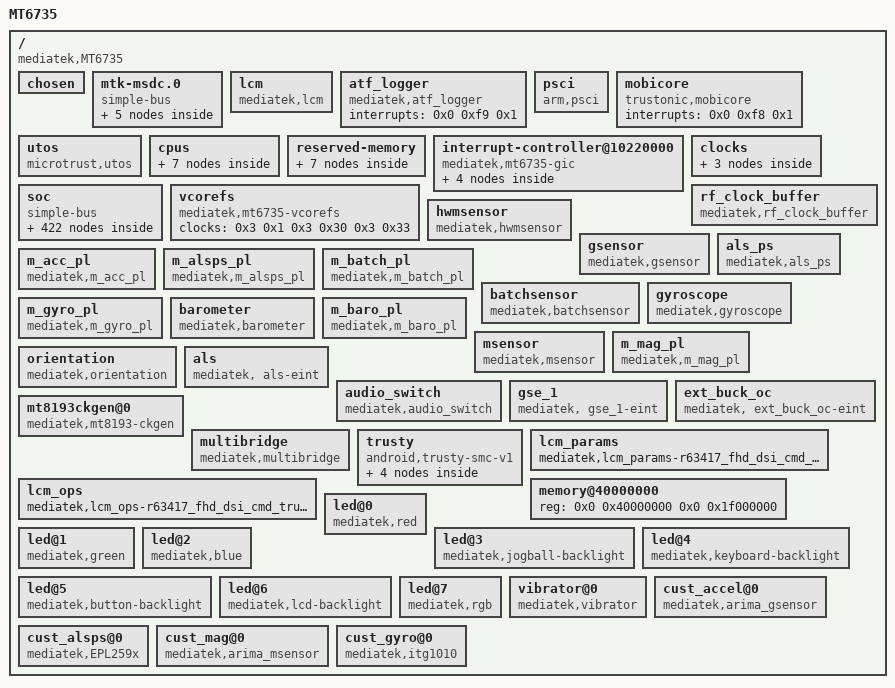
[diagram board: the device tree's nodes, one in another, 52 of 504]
/dts-v1/;

/ {
	model = "MT6735";
	compatible = "mediatek,MT6735";
	interrupt-parent = <0x1>;
	#address-cells = <0x2>;
	#size-cells = <0x2>;

	chosen {
		bootargs = "console=tty0 console=ttyMT0,921600n1 root=/dev/ram initrd=0x44000000,0x300000 loglevel=8 androidboot.hardware=mt6735";
	};

	mtk-msdc.0 {
		compatible = "simple-bus";
		#address-cells = <0x1>;
		#size-cells = <0x1>;
		ranges = <0x0 0x0 0x0 0xffffffff>;

		msdc0@11230000 {
			compatible = "mediatek,mt6735-mmc";
			reg = <0x11230000 0x10000 0x10000e84 0x2>;
			interrupts = <0x0 0x4f 0x8>;
			status = "okay";
			clocks = <0x2 0xe 0x3 0xd 0x3 0x29 0x3 0x2b 0x3 0x2c>;
			clock-names = "MSDC0-CLOCK", "MSDC0_PLL_SEL", "MSDC0_PLL_800M", "MSDC0_PLL_400M", "MSDC0_PLL_200M";
			clk_src = [02];
			bus-width = <0x8>;
			max-frequency = <0xbebc200>;
			cap-mmc-highspeed;
			msdc-sys-suspend;
			mmc-ddr-1_8v;
			mmc-hs200-1_8v;
			mmc-hs400-1_8v;
			non-removable;
			pinctl = <0x4>;
			register_setting = <0x5>;
			host_function = [00];
			bootable;
		};

		msdc1@11240000 {
			compatible = "mediatek,mt6735-mmc";
			reg = <0x11240000 0x10000 0x10000e84 0x2>;
			interrupts = <0x0 0x50 0x8>;
			status = "okay";
			clocks = <0x2 0xf>;
			clock-names = "MSDC1-CLOCK";
			clk_src = [02];
			bus-width = <0x4>;
			max-frequency = <0xbebc200>;
			msdc-sys-suspend;
			cap-sd-highspeed;
			sd-uhs-sdr12;
			sd-uhs-sdr25;
			sd-uhs-sdr50;
			sd-uhs-sdr104;
			sd-uhs-ddr50;
			pinctl = <0x6>;
			pinctl_sdr104 = <0x7>;
			pinctl_sdr50 = <0x8>;
			pinctl_ddr50 = <0x9>;
			register_setting = <0xa>;
			host_function = [01];
			cd_level = [00];
			cd-gpios = <0xb 0x5 0x0>;
		};

		msdc2@11250000 {
			compatible = "mediatek,mt6735-mmc";
			reg = <0x11250000 0x10000 0x10000e84 0x2>;
			interrupts = <0x0 0x51 0x8>;
			status = "disabled";
			clocks = <0x2 0x10>;
			clock-names = "MSDC2-CLOCK";
		};

		msdc3@11260000 {
			compatible = "mediatek,mt6735-mmc";
			reg = <0x11260000 0x10000 0x10000e84 0x2>;
			interrupts = <0x0 0x52 0x8>;
			status = "okay";
			clocks = <0x2 0x11>;
			clock-names = "MSDC3-CLOCK";
			clk_src = [02];
			bus-width = <0x4>;
			max-frequency = <0x2faf080>;
			cap-sd-highspeed;
			sd-uhs-sdr12;
			sd-uhs-sdr25;
			sd-uhs-sdr50;
			host_function = [02];
			non-removable;
		};

		default {
			compatible = "mediatek, msdc1_ins-eint";
			interrupt-parent = <0xc>;
			interrupts = <0x5 0x8>;
			debounce = <0x5 0x3e8>;
			status = "okay";
		};
	};

	lcm {
		compatible = "mediatek,lcm";
	};

	atf_logger {
		compatible = "mediatek,atf_logger";
		interrupts = <0x0 0xf9 0x1>;
	};

	psci {
		compatible = "arm,psci";
		method = "smc";
		cpu_suspend = <0x84000001>;
		cpu_off = <0x84000002>;
		cpu_on = <0x84000003>;
		affinity_info = <0x84000004>;
	};

	mobicore {
		compatible = "trustonic,mobicore";
		interrupts = <0x0 0xf8 0x1>;
	};

	utos {
		compatible = "microtrust,utos";
		interrupts = <0x0 0xf4 0x1 0x0 0xf5 0x1 0x0 0xf6 0x1 0x0 0xfa 0x1 0x0 0xfb 0x1 0x0 0xfc 0x1 0x0 0xfd 0x1 0x0 0xff 0x1>;
	};

	cpus {
		#address-cells = <0x1>;
		#size-cells = <0x0>;

		cpu@000 {
			device_type = "cpu";
			compatible = "arm,cortex-a53";
			reg = <0x0>;
			enable-method = "mt-boot";
			cpu-idle-states = <0xd 0xd 0xe 0xe>;
			cpu-release-addr = <0x0 0x40000200>;
			clock-frequency = "M|m";
			linux,phandle = <0xf>;
			phandle = <0xf>;
		};

		cpu@001 {
			device_type = "cpu";
			compatible = "arm,cortex-a53";
			reg = <0x1>;
			enable-method = "mt-boot";
			cpu-idle-states = <0xd 0xd 0xe 0xe>;
			cpu-release-addr = <0x0 0x40000200>;
			clock-frequency = "M|m";
			linux,phandle = <0x10>;
			phandle = <0x10>;
		};

		cpu@002 {
			device_type = "cpu";
			compatible = "arm,cortex-a53";
			reg = <0x2>;
			enable-method = "mt-boot";
			cpu-idle-states = <0xd 0xd 0xe 0xe>;
			cpu-release-addr = <0x0 0x40000200>;
			clock-frequency = "M|m";
			linux,phandle = <0x11>;
			phandle = <0x11>;
		};

		cpu@003 {
			device_type = "cpu";
			compatible = "arm,cortex-a53";
			reg = <0x3>;
			enable-method = "mt-boot";
			cpu-idle-states = <0xd 0xd 0xe 0xe>;
			cpu-release-addr = <0x0 0x40000200>;
			clock-frequency = "M|m";
			linux,phandle = <0x12>;
			phandle = <0x12>;
		};

		idle-states {
			entry-method = "arm,psci";

			cpu-sleep-0-0 {
				compatible = "arm,idle-state";
				arm,psci-suspend-param = <0x10000>;
				entry-latency-us = <0x258>;
				exit-latency-us = <0x258>;
				min-residency-us = <0x4b0>;
				linux,phandle = <0xe>;
				phandle = <0xe>;
			};

			cluster-sleep-0 {
				compatible = "arm,idle-state";
				arm,psci-suspend-param = <0x1010000>;
				entry-latency-us = <0x320>;
				exit-latency-us = <0x3e8>;
				min-residency-us = <0x7d0>;
				linux,phandle = <0xd>;
				phandle = <0xd>;
			};
		};
	};

	reserved-memory {
		#address-cells = <0x2>;
		#size-cells = <0x2>;
		ranges;

		atf-reserved-memory@43000000 {
			compatible = "mediatek,mt6735-atf-reserved-memory", "mediatek,mt6735m-atf-reserved-memory", "mediatek,mt6753-atf-reserved-memory";
			no-map;
			reg = <0x0 0x43000000 0x0 0x30000>;
		};

		ram_console-reserved-memory@43f00000 {
			compatible = "mediatek,ram_console";
			reg = <0x0 0x43f00000 0x0 0x10000>;
		};

		pstore-reserved-memory@43f10000 {
			compatible = "mediatek,pstore";
			reg = <0x0 0x43f10000 0x0 0xe0000>;
		};

		minirdump-reserved-memory@43ff0000 {
			compatible = "mediatek,minirdump";
			reg = <0x0 0x43ff0000 0x0 0x10000>;
		};

		reserve-memory-ccci_md1 {
			compatible = "mediatek,reserve-memory-ccci_md1";
			no-map;
			size = <0x0 0x3810000>;
			alignment = <0x0 0x2000000>;
			alloc-ranges = <0x0 0x40000000 0x0 0xc0000000>;
		};

		consys-reserve-memory {
			compatible = "mediatek,consys-reserve-memory";
			no-map;
			size = <0x0 0x100000>;
			alignment = <0x0 0x200000>;
		};

		reserve-memory-ccci_md3 {
			compatible = "mediatek,reserve-memory-ccci_md3";
			no-map;
			size = <0x0 0xb00000>;
			alignment = <0x0 0x2000000>;
			alloc-ranges = <0x0 0x40000000 0x0 0xc0000000>;
		};
	};

	interrupt-controller@10220000 {
		compatible = "mediatek,mt6735-gic";
		#interrupt-cells = <0x3>;
		#address-cells = <0x0>;
		interrupt-controller;
		reg = <0x0 0x10221000 0x0 0x1000 0x0 0x10222000 0x0 0x1000 0x0 0x10200620 0x0 0x1000>;
		mediatek,wdt_irq = <0xa0>;
		linux,phandle = <0x1>;
		phandle = <0x1>;

		gic-cpuif@0 {
			compatible = "arm,gic-cpuif";
			cpuif-id = <0x0>;
			cpu = <0xf>;
		};

		gic-cpuif@1 {
			compatible = "arm,gic-cpuif";
			cpuif-id = <0x1>;
			cpu = <0x10>;
		};

		gic-cpuif@2 {
			compatible = "arm,gic-cpuif";
			cpuif-id = <0x2>;
			cpu = <0x11>;
		};

		gic-cpuif@3 {
			compatible = "arm,gic-cpuif";
			cpuif-id = <0x3>;
			cpu = <0x12>;
		};
	};

	clocks {

		clk_null {
			compatible = "fixed-clock";
			#clock-cells = <0x0>;
			clock-frequency = <0x0>;
		};

		clk26m {
			compatible = "fixed-clock";
			#clock-cells = <0x0>;
			clock-frequency = <0x18cba80>;
			linux,phandle = <0x3d>;
			phandle = <0x3d>;
		};

		clk32k {
			compatible = "fixed-clock";
			#clock-cells = <0x0>;
			clock-frequency = <0x7d00>;
		};
	};

	soc {
		compatible = "simple-bus";
		#address-cells = <0x1>;
		#size-cells = <0x1>;
		ranges = <0x0 0x0 0x0 0xffffffff>;

		topckgen@10210000 {
			compatible = "mediatek,mt6735-topckgen";
			reg = <0x10210000 0x1000>;
			#clock-cells = <0x1>;
			linux,phandle = <0x3>;
			phandle = <0x3>;
		};

		chipid@08000000 {
			compatible = "mediatek,chipid";
			reg = <0x8000000 0x4 0x8000004 0x4 0x8000008 0x4 0x800000c 0x4>;
		};

		infrasys@10000000 {
			compatible = "mediatek,mt6735-infrasys";
			reg = <0x10000000 0x1000>;
			#clock-cells = <0x1>;
			linux,phandle = <0x19>;
			phandle = <0x19>;
		};

		scpsys@10000000 {
			compatible = "mediatek,mt6735-scpsys";
			reg = <0x10000000 0x1000 0x10006000 0x1000>;
			#clock-cells = <0x1>;
			linux,phandle = <0x13>;
			phandle = <0x13>;
		};

		infracfg_ao@10000000 {
			compatible = "mediatek,infracfg_ao";
			reg = <0x10000000 0x1000>;
		};

		usb2jtag@10000000 {
			compatible = "mediatek,usb2jtag_v1";
			reg = <0x10000000 0x1000 0x11210000 0x1000>;
		};

		pwrap@10001000 {
			compatible = "mediatek,PWRAP";
			reg = <0x10001000 0x1000>;
			interrupts = <0x0 0xa3 0x4>;
		};

		perisys@10002000 {
			compatible = "mediatek,mt6735-perisys";
			reg = <0x10002000 0x1000>;
			#clock-cells = <0x1>;
			linux,phandle = <0x2>;
			phandle = <0x2>;
		};

		hacc@10008000 {
			compatible = "mediatek,hacc";
			reg = <0x10008000 0x1000>;
			interrupts = <0x0 0xae 0x8>;
		};

		pericfg@10002000 {
			compatible = "mediatek,pericfg";
			reg = <0x10002000 0x1000>;
		};

		keypad@10003000 {
			compatible = "mediatek,mt6735-keypad";
			reg = <0x10003000 0x1000>;
			interrupts = <0x0 0xa4 0x2>;
			mediatek,kpd-key-debounce = <0x400>;
			mediatek,kpd-sw-pwrkey = <0x74>;
			mediatek,kpd-hw-pwrkey = <0x8>;
			mediatek,kpd-sw-rstkey = <0x73>;
			mediatek,kpd-hw-rstkey = <0x11>;
			mediatek,kpd-use-extend-type = <0x0>;
			mediatek,kpd-hw-map-num = <0x48>;
			mediatek,kpd-hw-init-map = <0x0 0x72 0x0 0x0 0x0 0x0 0x0 0x0 0x0 0x0 0x0 0x0 0x0 0x0 0x0 0x0 0x0 0x0 0x0 0x0 0x0 0x0 0x0 0x0 0x0 0x0 0x0 0x0 0x0 0x0 0x0 0x0 0x0 0x0 0x0 0x0 0x0 0x0 0x0 0x0 0x0 0x0 0x0 0x0 0x0 0x0 0x0 0x0 0x0 0x0 0x0 0x0 0x0 0x0 0x0 0x0 0x0 0x0 0x0 0x0 0x0 0x0 0x0 0x0 0x0 0x0 0x0 0x0 0x0 0x0 0x0 0x0>;
			mediatek,kpd-pwrkey-eint-gpio = <0x0>;
			mediatek,kpd-pwkey-gpio-din = <0x0>;
			mediatek,kpd-hw-dl-key0 = <0x11>;
			mediatek,kpd-hw-dl-key1 = <0x1>;
			mediatek,kpd-hw-dl-key2 = <0x8>;
			mediatek,kpd-hw-recovery-key = <0x11>;
			mediatek,kpd-hw-factory-key = <0x1>;
			status = "okay";
		};

		apxgpt@10004000 {
			compatible = "mediatek,mt6735-apxgpt";
			reg = <0x10004000 0x1000>;
			interrupts = <0x0 0x98 0x8>;
			clock-frequency = <0xc65d40>;
		};

		eintc@10005000 {
			compatible = "mediatek,mt-eic";
			reg = <0x10005000 0x1000>;
			interrupts = <0x0 0x99 0x4>;
			#interrupt-cells = <0x2>;
			interrupt-controller;
			mediatek,max_eint_num = <0xd5>;
			mediatek,mapping_table_entry = <0x0>;
			mediatek,debtime_setting_entry = <0xa>;
			mediatek,debtime_setting_array = <0x0 0x7d 0x1 0xfa 0x2 0x1f4 0x3 0x3e8 0x4 0x3e80 0x5 0x7d00 0x6 0xfa00 0x7 0x1f400 0x8 0x3e800 0x9 0x7d000>;
			linux,phandle = <0xc>;
			phandle = <0xc>;

			pmic@206 {
				compatible = "mediatek, pmic-eint";
				interrupt-parent = <0xc>;
				interrupts = <0xce 0x4>;
				debounce = <0xce 0x3e8>;
			};

			MD1_SIM1_HOT_PLUG_EINT@0 {
				compatible = "mediatek,MD1_SIM1_HOT_PLUG_EINT-eint";
				interrupts = <0x0 0x4>;
				debounce = <0x0 0x186a0>;
				dedicated = <0x0 0x0>;
				src_pin = <0x0 0x1>;
				sockettype = <0x0 0x0>;
				status = "okay";
			};
		};

		sleep@10006000 {
			compatible = "mediatek,sleep";
			reg = <0x10006000 0x1000>;
			interrupts = <0x0 0xa5 0x8 0x0 0xa6 0x8 0x0 0xa7 0x8 0x0 0xa8 0x8>;
		};

		mdcldma@1000A000 {
			compatible = "mediatek,mdcldma";
			reg = <0x1000a000 0x1000 0x1000b000 0x1000 0x1021a000 0x1000 0x1021b000 0x1000 0x1020a000 0x1000 0x1020b000 0x1000>;
			interrupts = <0x0 0x91 0x4 0x0 0x8c 0x8 0x0 0xdd 0x2>;
			mediatek,md_id = <0x0>;
			mediatek,cldma_capability = <0x6>;
			mediatek,md_smem_size = <0x10000>;
			clocks = <0x13 0x1>;
			clock-names = "scp-sys-md1-main";
			pinctrl-names = "default", "vsram_output_low", "vsram_output_high", "RFIC0_01_mode", "RFIC0_04_mode";
			pinctrl-0 = <0x14>;
			pinctrl-1 = <0x15>;
			pinctrl-2 = <0x16>;
			pinctrl-3 = <0x17>;
			pinctrl-4 = <0x18>;
		};

		mcucfg@10200000 {
			compatible = "mediatek,mcucfg";
			reg = <0x10200000 0x200>;
			interrupts = <0x0 0x47 0x4>;
		};

		cpuxgpt@10200000 {
			compatible = "mediatek,mt6735-cpuxgpt";
			reg = <0x10200000 0x1000>;
			interrupts = <0x0 0x40 0x4 0x0 0x41 0x4 0x0 0x42 0x4 0x0 0x43 0x4 0x0 0x44 0x4 0x0 0x45 0x4 0x0 0x46 0x4 0x0 0x47 0x4>;
		};

		lastpc@10200000 {
			compatible = "mediatek,mt6735-mcucfg";
			reg = <0x10200000 0x200>;
			interrupts = <0x0 0x47 0x4>;
		};

		emi@10203000 {
			compatible = "mediatek,emi";
			reg = <0x10203000 0x1000>;
			interrupts = <0x0 0x88 0x4>;
		};

		sys_cirq@10204000 {
			compatible = "mediatek,mt6735-sys_cirq";
			reg = <0x10204000 0x1000>;
			interrupts = <0x0 0xe7 0x8>;
			mediatek,cirq_num = <0x9f>;
			mediatek,spi_start_offset = <0x48>;
		};

		m4u@10205000 {
			cell-index = <0x0>;
			compatible = "mediatek,m4u";
			reg = <0x10205000 0x1000>;
			interrupts = <0x0 0x92 0x8>;
			clocks = <0x19 0x9 0x1a 0x1 0x1a 0x2 0x1b 0x1 0x1b 0x2 0x1c 0x1 0x1d 0x2 0x1d 0x1>;
			clock-names = "infra_m4u", "smi_common", "m4u_disp0_smi_larb0", "m4u_vdec0_vdec", "m4u_vdec1_larb", "m4u_img_image_larb2_smi", "m4u_venc_venc", "m4u_venc_larb";
		};

		efusec@10206000 {
			compatible = "mediatek,efusec";
			reg = <0x10206000 0x1000>;
		};

		devapc@10207000 {
			compatible = "mediatek,devapc";
			reg = <0x10207000 0x1000>;
			interrupts = <0x0 0x86 0x8>;
			clocks = <0x19 0x5>;
			clock-names = "devapc-main";
		};

		bus_dbg@10208000 {
			compatible = "mediatek,bus_dbg-v1";
			reg = <0x10208000 0x1000>;
			interrupts = <0x0 0x89 0x8>;
		};

		apmixedsys@10209000 {
			compatible = "mediatek,mt6735-apmixedsys";
			reg = <0x10209000 0x1000>;
			#clock-cells = <0x1>;
			linux,phandle = <0x3c>;
			phandle = <0x3c>;
		};

		apmixed@10209000 {
			compatible = "mediatek,apmixed";
			reg = <0x10209000 0x1000>;
		};

		fhctl@10209f00 {
			compatible = "mediatek,fhctl";
			reg = <0x10209f00 0x100>;
		};

		dramc_nao@1020e000 {
			compatible = "mediatek,mt6735-dramc_nao";
			reg = <0x1020e000 0x1000>;
		};

		cksys@10210000 {
			compatible = "mediatek,cksys";
			reg = <0x10210000 0x1000>;
		};

		syscfg_pctl_a@10211000 {
			compatible = "mediatek,mt6735-pctl-a-syscfg", "syscon";
			reg = <0x0 0x9bceb8 0x0 0x3e8>;
			linux,phandle = <0x1e>;
			phandle = <0x1e>;
		};

		pinctrl@10211000 {
			compatible = "mediatek,mt6735-pinctrl";
			reg = <0x0 0x9bceb8 0x0 0x3e8>;
			mediatek,pctl-regmap = <0x1e>;
			pins-are-numbered;
			gpio-controller;
			#gpio-cells = <0x2>;
			linux,phandle = <0xb>;
			phandle = <0xb>;

			8193ckgen_default {
				linux,phandle = <0x8e>;
				phandle = <0x8e>;
			};

			8193ckgen_gpio {
				linux,phandle = <0x8f>;
				phandle = <0x8f>;

				pins_cmd_dat {
					pins = <0x0>;
					slew-rate = <0x1>;
					bias-pull-up = <0x0>;
					output-high;
				};
			};

			8193ckgen_dpi {
				linux,phandle = <0x90>;
				phandle = <0x90>;

				pins_cmd_dat {
					pins = <0x2>;
				};
			};

			ssw0default {
				linux,phandle = <0x73>;
				phandle = <0x73>;
			};

			ssw@1 {
				linux,phandle = <0x74>;
				phandle = <0x74>;

				pins_cmd0_dat {
					pins = <0x805>;
				};

				pins_cmd1_dat {
					pins = <0x904>;
				};
			};

			ssw@2 {
				linux,phandle = <0x75>;
				phandle = <0x75>;

				pins_cmd0_dat {
					pins = <0x802>;
				};

				pins_cmd1_dat {
					pins = <0x904>;
				};
			};

			ssw@3 {
				linux,phandle = <0x76>;
				phandle = <0x76>;

				pins_cmd0_dat {
					pins = <0xa301>;
					slew-rate = <0x1>;
				};

				pins_cmd1_dat {
					pins = <0xa401>;
					slew-rate = <0x1>;
				};

				pins_cmd2_dat {
					pins = <0xa501>;
					slew-rate = <0x0>;
					bias-pull-up = <0x0>;
				};

				pins_cmd3_dat {
					pins = <0xa001>;
					slew-rate = <0x1>;
				};

				pins_cmd4_dat {
					pins = <0xa101>;
					slew-rate = <0x1>;
				};

				pins_cmd5_dat {
					pins = <0xa201>;
					slew-rate = <0x0>;
					bias-pull-up = <0x0>;
				};
			};

			ssw@4 {
				linux,phandle = <0x77>;
				phandle = <0x77>;

				pins_cmd0_dat {
					pins = <0xa304>;
				};

				pins_cmd1_dat {
					pins = <0xa404>;
				};

				pins_cmd2_dat {
					pins = <0xa504>;
				};

				pins_cmd3_dat {
					pins = <0xa001>;
				};

				pins_cmd4_dat {
					pins = <0xa101>;
				};

				pins_cmd5_dat {
					pins = <0xa201>;
				};
			};

			vsram0default {
				linux,phandle = <0x14>;
				phandle = <0x14>;
			};

			vsram@1 {
				linux,phandle = <0x15>;
				phandle = <0x15>;

				pins_cmd_dat {
					pins = <0x8c00>;
					slew-rate = <0x1>;
					output-low;
				};
			};

			vsram@2 {
				linux,phandle = <0x16>;
				phandle = <0x16>;

				pins_cmd_dat {
					pins = <0x8c00>;
					slew-rate = <0x1>;
					output-high;
				};
			};

			clockbuf@1 {
				linux,phandle = <0x17>;
				phandle = <0x17>;

				pins_cmd0_dat {
					pins = <0x6e01>;
				};

				pins_cmd1_dat {
					pins = <0x6f01>;
				};

				pins_cmd2_dat {
					pins = <0x7001>;
				};

				pins_cmd3_dat {
					pins = <0x7101>;
				};

				pins_cmd4_dat {
					pins = <0x7201>;
				};
			};

			clockbuf@2 {
				linux,phandle = <0x18>;
				phandle = <0x18>;

				pins_cmd0_dat {
					pins = <0x6e04>;
				};

				pins_cmd1_dat {
					pins = <0x6f04>;
				};

				pins_cmd2_dat {
					pins = <0x7004>;
				};

				pins_cmd3_dat {
					pins = <0x7104>;
				};

				pins_cmd4_dat {
					pins = <0x7204>;
				};
			};

			uart0gpiodefault {
				linux,phandle = <0x21>;
				phandle = <0x21>;
			};

			uart0_rx_set@gpio74 {
				linux,phandle = <0x22>;
				phandle = <0x22>;

				pins_cmd_dat {
					pins = <0x4a01>;
				};
			};

			uart0_rx_clear@gpio74 {
				linux,phandle = <0x23>;
				phandle = <0x23>;

				pins_cmd_dat {
					pins = <0x4a00>;
					slew-rate = <0x1>;
					output-high;
				};
			};

			uart0_tx_set@gpio75 {
				linux,phandle = <0x24>;
				phandle = <0x24>;

				pins_cmd_dat {
					pins = <0x4b01>;
				};
			};

			uart0_tx_clear@gpio75 {
				linux,phandle = <0x25>;
				phandle = <0x25>;

				pins_cmd_dat {
					pins = <0x4b00>;
					slew-rate = <0x1>;
					output-high;
				};
			};

			uart1gpiodefault {
				linux,phandle = <0x26>;
				phandle = <0x26>;
			};

			uart1_rx_set@gpio76 {
				linux,phandle = <0x27>;
				phandle = <0x27>;

				pins_cmd_dat {
					pins = <0x4c01>;
				};
			};

			uart1_rx_clear@gpio76 {
				linux,phandle = <0x28>;
				phandle = <0x28>;

				pins_cmd_dat {
					pins = <0x4c00>;
					slew-rate = <0x1>;
					output-high;
				};
			};

			uart1_tx_set@gpio77 {
				linux,phandle = <0x29>;
				phandle = <0x29>;

				pins_cmd_dat {
					pins = <0x4d01>;
				};
			};

			uart1_tx_clear@gpio77 {
				linux,phandle = <0x2a>;
				phandle = <0x2a>;

				pins_cmd_dat {
					pins = <0x4d00>;
					slew-rate = <0x1>;
					output-high;
				};
			};

			uart2gpiodefault {
				linux,phandle = <0x2b>;
				phandle = <0x2b>;
			};

			uart2_rx_set@gpio57 {
				linux,phandle = <0x2c>;
				phandle = <0x2c>;

				pins_cmd_dat {
					pins = <0x3901>;
				};
			};

			uart2_rx_clear@gpio57 {
				linux,phandle = <0x2d>;
				phandle = <0x2d>;

				pins_cmd_dat {
					pins = <0x3900>;
					slew-rate = <0x1>;
					output-high;
				};
			};

			uart2_tx_set@gpio58 {
				linux,phandle = <0x2e>;
				phandle = <0x2e>;

				pins_cmd_dat {
					pins = <0x3a01>;
				};
			};

			uart2_tx_clear@gpio58 {
				linux,phandle = <0x2f>;
				phandle = <0x2f>;

				pins_cmd_dat {
					pins = <0x3a00>;
					slew-rate = <0x1>;
					output-high;
				};
			};

			uart3gpiodefault {
				linux,phandle = <0x30>;
				phandle = <0x30>;
			};

			uart3_rx_set@gpio59 {
				linux,phandle = <0x31>;
				phandle = <0x31>;

				pins_cmd_dat {
					pins = <0x3b01>;
				};
			};

			uart3_rx_clear@gpio59 {
				linux,phandle = <0x32>;
				phandle = <0x32>;

				pins_cmd_dat {
					pins = <0x3b00>;
					slew-rate = <0x1>;
					output-high;
				};
			};

			uart3_tx_set@gpio60 {
				linux,phandle = <0x33>;
				phandle = <0x33>;

				pins_cmd_dat {
					pins = <0x3c01>;
				};
			};

			uart3_tx_clear@gpio60 {
				linux,phandle = <0x34>;
				phandle = <0x34>;

				pins_cmd_dat {
					pins = <0x3c00>;
					slew-rate = <0x1>;
					output-high;
				};
			};

			irtx_gpio_led_def@gpio19 {
				linux,phandle = <0x1f>;
				phandle = <0x1f>;

				pins_cmd_dat {
					pins = <0x1300>;
					slew-rate = <0x1>;
					bias-disable;
					output-high;
					input-schmitt-enable = <0x0>;
				};
			};

			irtx_gpio_led_set@gpio19 {
				linux,phandle = <0x20>;
				phandle = <0x20>;

				pins_cmd_dat {
					pins = <0x1302>;
				};
			};

			alspspincfg {
				linux,phandle = <0x8b>;
				phandle = <0x8b>;

				pins_cmd_dat {
					pins = <0x4100>;
					slew-rate = <0x0>;
					bias-pull-up = <0x0>;
				};
			};

			alspsdefaultcfg {
				linux,phandle = <0x8a>;
				phandle = <0x8a>;
			};

			gyropincfg {
				linux,phandle = <0x8d>;
				phandle = <0x8d>;

				pins_cmd_dat {
					pins = <0x4300>;
					slew-rate = <0x0>;
					bias-pull-down = <0x0>;
				};
			};

			gyrodefaultcfg {
				linux,phandle = <0x8c>;
				phandle = <0x8c>;
			};

			eint0default {
				linux,phandle = <0x65>;
				phandle = <0x65>;
			};

			eint@0 {
				linux,phandle = <0x66>;
				phandle = <0x66>;

				pins_cmd_dat {
					pins = <0x600>;
					slew-rate = <0x0>;
					bias-disable;
				};
			};

			eintoutput0 {
				linux,phandle = <0x67>;
				phandle = <0x67>;

				pins_cmd_dat {
					pins = <0xa00>;
					slew-rate = <0x1>;
					output-low;
				};
			};

			eintoutput1 {
				linux,phandle = <0x68>;
				phandle = <0x68>;

				pins_cmd_dat {
					pins = <0xa00>;
					slew-rate = <0x1>;
					output-high;
				};
			};

			rstoutput0 {
				linux,phandle = <0x69>;
				phandle = <0x69>;

				pins_cmd_dat {
					pins = <0x3e00>;
					slew-rate = <0x1>;
					output-low;
				};
			};

			rstoutput1 {
				linux,phandle = <0x6a>;
				phandle = <0x6a>;

				pins_cmd_dat {
					pins = <0x3e00>;
					slew-rate = <0x1>;
					output-high;
				};
			};

			eininput1 {
				linux,phandle = <0x6b>;
				phandle = <0x6b>;

				pins_cmd_dat {
					pins = <0xa00>;
					slew-rate = <0x0>;
					bias-disable;
				};
			};

			audiodefault {
				linux,phandle = <0x3e>;
				phandle = <0x3e>;
			};

			pmicclkmode0 {
				linux,phandle = <0x3f>;
				phandle = <0x3f>;

				pins_cmd0_dat {
					pins = <0x8f00>;
				};

				pins_cmd1_dat {
					pins = <0x9000>;
				};

				pins_cmd2_dat {
					pins = <0x9100>;
				};
			};

			pmicclkmode1 {
				linux,phandle = <0x40>;
				phandle = <0x40>;

				pins_cmd0_dat {
					pins = <0x8f01>;
				};

				pins_cmd1_dat {
					pins = <0x9001>;
				};

				pins_cmd2_dat {
					pins = <0x9101>;
				};
			};

			audi2s1mode0 {
				linux,phandle = <0x41>;
				phandle = <0x41>;

				pins_cmd0_dat {
					pins = <0x4e00>;
				};

				pins_cmd1_dat {
					pins = <0x4f00>;
				};

				pins_cmd2_dat {
					pins = <0x5000>;
				};
			};

			audi2s1mode1 {
				linux,phandle = <0x42>;
				phandle = <0x42>;

				pins_cmd0_dat {
					pins = <0x4e01>;
				};

				pins_cmd1_dat {
					pins = <0x4f01>;
				};

				pins_cmd2_dat {
					pins = <0x5001>;
				};
			};

			audexamphigh {
				linux,phandle = <0x43>;
				phandle = <0x43>;

				pins_cmd_dat {
					pins = <0x8100>;
					slew-rate = <0x1>;
					output-high;
				};
			};

			audexamplow {
				linux,phandle = <0x44>;
				phandle = <0x44>;

				pins_cmd_dat {
					pins = <0x8100>;
					slew-rate = <0x1>;
					output-low;
				};
			};

			audexam2phigh {
				linux,phandle = <0x45>;
				phandle = <0x45>;

				pins_cmd_dat {
					pins = <0x8000>;
					slew-rate = <0x1>;
					output-high;
				};
			};

			audexamp2low {
				linux,phandle = <0x46>;
				phandle = <0x46>;

				pins_cmd_dat {
					pins = <0x8000>;
					slew-rate = <0x1>;
					output-low;
				};
			};

			audrcvspkhigh {
				linux,phandle = <0x47>;
				phandle = <0x47>;

				pins_cmd_dat {
					pins = <0x7800>;
					slew-rate = <0x1>;
					output-high;
				};
			};

			audrcvspklow {
				linux,phandle = <0x48>;
				phandle = <0x48>;

				pins_cmd_dat {
					pins = <0x7800>;
					slew-rate = <0x1>;
					output-low;
				};
			};

			cam0@0 {
				linux,phandle = <0x58>;
				phandle = <0x58>;

				pins_cmd_dat {
					pins = <0x2c00>;
					slew-rate = <0x1>;
					output-low;
				};
			};

			cam0@1 {
				linux,phandle = <0x59>;
				phandle = <0x59>;

				pins_cmd_dat {
					pins = <0x2c00>;
					slew-rate = <0x1>;
					output-high;
				};
			};

			cam1@0 {
				linux,phandle = <0x5a>;
				phandle = <0x5a>;

				pins_cmd_dat {
					pins = <0x3d00>;
					slew-rate = <0x1>;
					output-low;
				};
			};

			cam1@1 {
				linux,phandle = <0x5b>;
				phandle = <0x5b>;

				pins_cmd_dat {
					pins = <0x3d00>;
					slew-rate = <0x1>;
					output-high;
				};
			};

			camdefault {
				linux,phandle = <0x57>;
				phandle = <0x57>;
			};

			default {
				linux,phandle = <0x60>;
				phandle = <0x60>;
			};

			gpslna@0 {
				linux,phandle = <0x61>;
				phandle = <0x61>;

				pins_cmd_dat {
					pins = <0x4f00>;
					slew-rate = <0x0>;
					bias-disable;
					output-low;
				};
			};

			gpslna@1 {
				linux,phandle = <0x62>;
				phandle = <0x62>;

				pins_cmd_dat {
					pins = <0x4f00>;
					slew-rate = <0x1>;
					output-high;
				};
			};

			gpslna@2 {
				linux,phandle = <0x63>;
				phandle = <0x63>;

				pins_cmd_dat {
					pins = <0x4f00>;
					slew-rate = <0x1>;
					output-low;
				};
			};

			mmc0@default {
				linux,phandle = <0x4>;
				phandle = <0x4>;

				pins_cmd {
					drive-strength = [02];
				};

				pins_dat {
					drive-strength = [02];
				};

				pins_clk {
					drive-strength = [02];
				};

				pins_rst {
					drive-strength = [02];
				};

				pins_ds {
					drive-strength = [02];
				};
			};

			mmc0@register_default {
				dat0rddly = [00];
				dat1rddly = [00];
				dat2rddly = [00];
				dat3rddly = [00];
				dat4rddly = [00];
				dat5rddly = [00];
				dat6rddly = [00];
				dat7rddly = [00];
				datwrddly = [00];
				cmdrrddly = [00];
				cmdrddly = [00];
				cmd_edge = [01];
				rdata_edge = [01];
				wdata_edge = [01];
				ett-hs200-cells = <0xc>;
				ett-hs200-default = <0xb0 0x380 0x0 0xb0 0x7c00 0x0 0xb4 0x38 0x1 0x4 0x2 0x0 0xf0 0x1f0000 0x7 0xf0 0x7c00000 0xb 0xb4 0x7 0x1 0xf0 0x1f 0xb 0x4 0x400 0x0 0xf8 0x1f000000 0x7 0xf0 0x1f00 0x9 0x4 0x4 0x0>;
				ett-hs400-cells = <0x8>;
				ett-hs400-default = <0xb0 0x380 0x0 0xb0 0x7c00 0x0 0x188 0x7c 0x2 0x188 0x1f000 0x10 0xb4 0x38 0x1 0x4 0x2 0x0 0xf0 0x1f0000 0x6 0xf0 0x7c00000 0x6>;
				linux,phandle = <0x5>;
				phandle = <0x5>;
			};

			mmc1@default {
				linux,phandle = <0x6>;
				phandle = <0x6>;

				pins_cmd {
					drive-strength = [03];
				};

				pins_dat {
					drive-strength = [03];
				};

				pins_clk {
					drive-strength = [03];
				};
			};

			mmc1@sdr104 {
				linux,phandle = <0x7>;
				phandle = <0x7>;

				pins_cmd {
					drive-strength = [02];
				};

				pins_dat {
					drive-strength = [02];
				};

				pins_clk {
					drive-strength = [03];
				};
			};

			mmc1@sdr50 {
				linux,phandle = <0x8>;
				phandle = <0x8>;

				pins_cmd {
					drive-strength = [02];
				};

				pins_dat {
					drive-strength = [02];
				};

				pins_clk {
					drive-strength = [03];
				};
			};

			mmc1@ddr50 {
				linux,phandle = <0x9>;
				phandle = <0x9>;

				pins_cmd {
					drive-strength = [02];
				};

				pins_dat {
					drive-strength = [02];
				};

				pins_clk {
					drive-strength = [03];
				};
			};

			mmc1@register_default {
				dat0rddly = [00];
				dat1rddly = [00];
				dat2rddly = [00];
				dat3rddly = [00];
				datwrddly = [00];
				cmdrrddly = [00];
				cmdrddly = [00];
				cmd_edge = [01];
				rdata_edge = [01];
				wdata_edge = [01];
				linux,phandle = <0xa>;
				phandle = <0xa>;
			};

			state_ven_high {
				linux,phandle = <0x6c>;
				phandle = <0x6c>;

				pins_cmd_dat {
					pins = <0xb00>;
					slew-rate = <0x1>;
					output-high;
				};
			};

			state_ven_low {
				linux,phandle = <0x6d>;
				phandle = <0x6d>;

				pins_cmd_dat {
					pins = <0xb00>;
					slew-rate = <0x1>;
					output-low;
				};
			};

			state_rst_high {
				linux,phandle = <0x6e>;
				phandle = <0x6e>;

				pins_cmd_dat {
					pins = <0xb00>;
					slew-rate = <0x1>;
					output-high;
				};
			};

			state_rst_low {
				linux,phandle = <0x6f>;
				phandle = <0x6f>;

				pins_cmd_dat {
					pins = <0xb00>;
					slew-rate = <0x1>;
					output-low;
				};
			};

			state_eint_high {
				linux,phandle = <0x70>;
				phandle = <0x70>;

				pins_cmd_dat {
					pins = <0xc00>;
					slew-rate = <0x1>;
					output-high;
				};
			};

			state_eint_low {
				linux,phandle = <0x71>;
				phandle = <0x71>;

				pins_cmd_dat {
					pins = <0xc00>;
					slew-rate = <0x1>;
					output-low;
				};
			};

			state_irq_init {
				linux,phandle = <0x72>;
				phandle = <0x72>;

				pins_cmd_dat {
					pins = <0x700>;
					slew-rate = <0x0>;
					bias-pull-down = <0x0>;
				};
			};

			usb_default {
				linux,phandle = <0x36>;
				phandle = <0x36>;
			};

			iddig_irq_init {
				linux,phandle = <0x37>;
				phandle = <0x37>;

				pins_cmd_dat {
					pins = <0x1>;
					slew-rate = <0x0>;
					bias-pull-up = <0x0>;
				};
			};

			drvvbus_init {
				linux,phandle = <0x38>;
				phandle = <0x38>;

				pins_cmd_dat {
					pins = <0x5300>;
					slew-rate = <0x1>;
					bias-pull-down = <0x0>;
				};
			};

			drvvbus_low {
				linux,phandle = <0x39>;
				phandle = <0x39>;

				pins_cmd_dat {
					pins = <0x5300>;
					slew-rate = <0x1>;
					output-low;
					bias-pull-down = <0x0>;
				};
			};

			drvvbus_high {
				linux,phandle = <0x3a>;
				phandle = <0x3a>;

				pins_cmd_dat {
					pins = <0x5300>;
					slew-rate = <0x1>;
					output-high;
					bias-pull-down = <0x0>;
				};
			};

			lcm_mode_default {
				linux,phandle = <0x4a>;
				phandle = <0x4a>;

				pins_cmd_dat {
					pins = <0x5000>;
				};
			};

			lcm_mode@0 {
				linux,phandle = <0x4b>;
				phandle = <0x4b>;

				pins_cmd_dat {
					pins = <0x5000>;
				};
			};

			lcm_mode@1 {
				linux,phandle = <0x4c>;
				phandle = <0x4c>;

				pins_cmd_dat {
					pins = <0x5001>;
				};
			};

			lcm_mode@2 {
				linux,phandle = <0x4d>;
				phandle = <0x4d>;

				pins_cmd_dat {
					pins = <0x5002>;
				};
			};

			lcm_mode@3 {
				linux,phandle = <0x4e>;
				phandle = <0x4e>;

				pins_cmd_dat {
					pins = <0x5003>;
				};
			};

			lcm_mode@4 {
				linux,phandle = <0x4f>;
				phandle = <0x4f>;

				pins_cmd_dat {
					pins = <0x5004>;
				};
			};

			lcm_mode@5 {
				linux,phandle = <0x50>;
				phandle = <0x50>;

				pins_cmd_dat {
					pins = <0x5005>;
				};
			};

			lcm_mode@6 {
				linux,phandle = <0x51>;
				phandle = <0x51>;

				pins_cmd_dat {
					pins = <0x5006>;
				};
			};

			lcm_mode@7 {
				linux,phandle = <0x52>;
				phandle = <0x52>;

				pins_cmd_dat {
					pins = <0x5007>;
				};
			};
		};

		gpio {
			compatible = "mediatek,gpio_usage_mapping";
			GPIO_SIM1_HOT_PLUG = <0x8>;
			GPIO_CMDAT1 = <0x2b>;
			GPIO_FDD_BAND_SUPPORT_DETECT_2ND_PIN = <0x52>;
			GPIO_FDD_BAND_SUPPORT_DETECT_1ST_PIN = <0x53>;
			GPIO_FDD_BAND_SUPPORT_DETECT_3RD_PIN = <0x57>;
			GPIO_SIM2_SCLK = <0xa0>;
			GPIO_SIM2_SRST = <0xa1>;
			GPIO_SIM2_SIO = <0xa2>;
			GPIO_SIM1_SCLK = <0xa3>;
			GPIO_SIM1_SRST = <0xa4>;
			GPIO_SIM1_SIO = <0xa5>;
		};

		gpio@10211000 {
			compatible = "mediatek,gpio";
			reg = <0x10211000 0x1000>;
		};

		toprgu@10212000 {
			compatible = "mediatek,mt6735-rgu";
			reg = <0x10212000 0x1000>;
			interrupts = <0x0 0x80 0x2>;
		};

		ddrphy@10213000 {
			compatible = "mediatek,mt6735-ddrphy";
			reg = <0x10213000 0x1000>;
		};

		dramc@10214000 {
			compatible = "mediatek,mt6735-dramc";
			reg = <0x10214000 0x1000>;
			clocks = <0x19 0x2>;
			clock-names = "infra-cqdma";
		};

		gcpu@10216000 {
			compatible = "mediatek,gcpu";
			reg = <0x10216000 0x1000>;
			interrupts = <0x0 0x96 0x8>;
		};

		gce@10217000 {
			compatible = "mediatek,gce";
			reg = <0x10217000 0x1000>;
			interrupts = <0x0 0x97 0x8 0x0 0x94 0x8>;
			disp_mutex_reg = <0x14014000 0x1000>;
			g3d_config_base = <0x13000000 0x0 0xffff0000>;
			mmsys_config_base = <0x14000000 0x1 0xffff0000>;
			disp_dither_base = <0x14010000 0x2 0xffff0000>;
			mm_na_base = <0x14020000 0x3 0xffff0000>;
			imgsys_base = <0x15000000 0x4 0xffff0000>;
			vdec_gcon_base = <0x16000000 0x5 0xffff0000>;
			venc_gcon_base = <0x17000000 0x6 0xffff0000>;
			conn_peri_base = <0x18000000 0x7 0xffff0000>;
			topckgen_base = <0x10000000 0x8 0xffff0000>;
			kp_base = <0x10010000 0x9 0xffff0000>;
			scp_sram_base = <0x10020000 0xa 0xffff0000>;
			infra_na3_base = <0x10030000 0xb 0xffff0000>;
			infra_na4_base = <0x10040000 0xc 0xffff0000>;
			scp_base = <0x10050000 0xd 0xffff0000>;
			mcucfg_base = <0x10200000 0xe 0xffff0000>;
			gcpu_base = <0x10210000 0xf 0xffff0000>;
			usb0_base = <0x11200000 0x10 0xffff0000>;
			usb_sif_base = <0x11210000 0x11 0xffff0000>;
			audio_base = <0x11220000 0x12 0xffff0000>;
			msdc0_base = <0x11230000 0x13 0xffff0000>;
			msdc1_base = <0x11240000 0x14 0xffff0000>;
			msdc2_base = <0x11250000 0x15 0xffff0000>;
			msdc3_base = <0x11260000 0x16 0xffff0000>;
			pwm_sw_base = <0x1100e000 0x63 0xfffff000>;
			mdp_rdma0_sof = <0x0>;
			mdp_rsz0_sof = <0x1>;
			mdp_rsz1_sof = <0x2>;
			dsi0_te_event = <0x3>;
			mdp_wdma_sof = <0x4>;
			mdp_wrot_sof = <0x5>;
			disp_ovl0_sof = <0x6>;
			disp_rdma0_sof = <0x7>;
			disp_rdma1_sof = <0x8>;
			disp_wdma0_sof = <0x9>;
			disp_ccorr_sof = <0xa>;
			disp_color_sof = <0xb>;
			disp_aal_sof = <0xc>;
			disp_gamma_sof = <0xd>;
			disp_dither_sof = <0xe>;
			disp_pwm0_sof = <0x10>;
			mdp_rdma0_frame_done = <0x11>;
			mdp_rsz0_frame_done = <0x12>;
			mdp_rsz1_frame_done = <0x13>;
			mdp_tdshp_frame_done = <0x14>;
			mdp_wdma_frame_done = <0x15>;
			mdp_wrot_write_frame_done = <0x16>;
			mdp_wrot_read_frame_done = <0x17>;
			disp_ovl0_frame_done = <0x18>;
			disp_rdma0_frame_done = <0x19>;
			disp_rdma1_frame_done = <0x1a>;
			disp_wdma0_frame_done = <0x1b>;
			disp_ccorr_frame_done = <0x1c>;
			disp_color_frame_done = <0x1d>;
			disp_aal_frame_done = <0x1e>;
			disp_gamma_frame_done = <0x1f>;
			disp_dither_frame_done = <0x20>;
			disp_dpi0_frame_done = <0x22>;
			stream_done_0 = <0x23>;
			stream_done_1 = <0x24>;
			stream_done_2 = <0x25>;
			stream_done_3 = <0x26>;
			stream_done_4 = <0x27>;
			stream_done_5 = <0x28>;
			stream_done_6 = <0x29>;
			stream_done_7 = <0x2a>;
			stream_done_8 = <0x2b>;
			stream_done_9 = <0x2c>;
			buf_underrun_event_0 = <0x2d>;
			buf_underrun_event_1 = <0x2e>;
			mdp_tdshp_sof = <0x2f>;
			isp_frame_done_p2_2 = <0x41>;
			isp_frame_done_p2_1 = <0x42>;
			isp_frame_done_p2_0 = <0x43>;
			isp_frame_done_p1_1 = <0x44>;
			isp_frame_done_p1_0 = <0x45>;
			camsv_2_pass1_done = <0x46>;
			camsv_1_pass1_done = <0x47>;
			seninf_cam1_2_3_fifo_full = <0x48>;
			seninf_cam0_fifo_full = <0x49>;
			venc_done = <0x81>;
			jpgenc_done = <0x82>;
			jpgdec_done = <0x83>;
			venc_mb_done = <0x84>;
			venc_128byte_cnt_done = <0x85>;
			apxgpt2_count = <0x10004028>;
			clocks = <0x19 0x2>;
			clock-names = "GCE";
		};

		cqdma@10217c00 {
			compatible = "mediatek,cqdma";
			reg = <0x10217c00 0xc00>;
			interrupts = <0x0 0x97 0x8>;
			nr_channel = <0x1>;
		};

		mcu_biu@10300000 {
			compatible = "mediatek,mt6735-mcu_biu";
			reg = <0x10300000 0x8000>;
		};

		cpu_dbgapb@10810000 {
			compatible = "mediatek,hw_dbg";
			num = <0x4>;
			reg = <0x10810000 0x1000 0x10910000 0x1000 0x10a10000 0x1000 0x10b10000 0x1000>;
		};

		adc_hw@11001000 {
			compatible = "mediatek,mt6735-auxadc";
			reg = <0x11001000 0x1000>;
			interrupts = <0x0 0x4c 0x2>;
			clocks = <0x2 0x1c>;
			clock-names = "auxadc-main";

			adc_channel@ {
				compatible = "mediatek,adc_channel";
				mediatek,temperature0 = <0x0>;
				mediatek,temperature1 = <0x1>;
				mediatek,adc_fdd_rf_params_dynamic_custom_ch = <0xc>;
				status = "okay";
			};
		};

		dbgapb_base@1011a000 {
			compatible = "mediatek,dbgapb_base";
			reg = <0x1011a000 0x100>;
		};

		dma@11000000 {
			compatible = "mediatek,ap_dma";
			reg = <0x11000000 0x1000>;
			interrupts = <0x0 0x72 0x8>;
		};

		btif_tx@11000880 {
			compatible = "mediatek,btif_tx";
			reg = <0x11000880 0x80>;
			interrupts = <0x0 0x71 0x8>;
		};

		btif_rx@11000900 {
			compatible = "mediatek,btif_rx";
			reg = <0x11000900 0x80>;
			interrupts = <0x0 0x72 0x8>;
		};

		irtx@11011000 {
			compatible = "mediatek,irtx";
			reg = <0x11011000 0x1000>;
			interrupts = <0x0 0x7c 0x4>;
			pwm_ch = <0x0>;
			clock-frequency = <0x18cba80>;
			clock-div = <0x1>;
			clocks = <0x2 0x1e>;
			clock-names = "clk-irtx-main";
			pinctrl-names = "irtx_gpio_default", "irtx_gpio_led_set";
			pinctrl-0 = <0x1f>;
			pinctrl-1 = <0x20>;
			status = "okay";
		};

		irtx-pwm {
			compatible = "mediatek,irtx-pwm";
			pwm_ch = <0x2>;
			pwm_data_invert = <0x0>;
		};

		irlearning-spi {
			compatible = "mediatek,irlearning-spi";
			spi_clock = <0x67f3540>;
			spi_data_invert = <0x0>;
			spi_cs_invert = <0x1>;
		};

		apuart0@11002000 {
			cell-index = <0x0>;
			compatible = "mediatek,mt6735-uart";
			reg = <0x11002000 0x1000 0x11000380 0x1000 0x11000400 0x80>;
			interrupts = <0x0 0x5b 0x8 0x0 0x67 0x8 0x0 0x68 0x8>;
			clock-frequency = <0x18cba80>;
			clock-div = <0x1>;
			clocks = <0x2 0x12 0x2 0xd>;
			clock-names = "uart0-main", "uart-apdma";
			pinctrl-names = "uart0_gpio_default", "uart0_rx_set", "uart0_rx_clear", "uart0_tx_set", "uart0_tx_clear";
			pinctrl-0 = <0x21>;
			pinctrl-1 = <0x22>;
			pinctrl-2 = <0x23>;
			pinctrl-3 = <0x24>;
			pinctrl-4 = <0x25>;
			status = "okay";
		};

		apuart1@11003000 {
			cell-index = <0x1>;
			compatible = "mediatek,mt6735-uart";
			reg = <0x11003000 0x1000 0x11000480 0x80 0x11000500 0x80>;
			interrupts = <0x0 0x5c 0x8 0x0 0x69 0x8 0x0 0x6a 0x8>;
			clock-frequency = <0x18cba80>;
			clock-div = <0x1>;
			clocks = <0x2 0x13>;
			clock-names = "uart1-main";
			pinctrl-names = "uart1_gpio_default", "uart1_rx_set", "uart1_rx_clear", "uart1_tx_set", "uart1_tx_clear";
			pinctrl-0 = <0x26>;
			pinctrl-1 = <0x27>;
			pinctrl-2 = <0x28>;
			pinctrl-3 = <0x29>;
			pinctrl-4 = <0x2a>;
			status = "okay";
		};

		apuart2@11004000 {
			cell-index = <0x2>;
			compatible = "mediatek,mt6735-uart";
			reg = <0x11004000 0x1000 0x11000580 0x80 0x11000600 0x80>;
			interrupts = <0x0 0x5d 0x8 0x0 0x6b 0x8 0x0 0x6c 0x8>;
			clock-frequency = <0x18cba80>;
			clock-div = <0x1>;
			clocks = <0x2 0x14>;
			clock-names = "uart2-main";
			pinctrl-names = "uart2_gpio_default", "uart2_rx_set", "uart2_rx_clear", "uart2_tx_set", "uart2_tx_clear";
			pinctrl-0 = <0x2b>;
			pinctrl-1 = <0x2c>;
			pinctrl-2 = <0x2d>;
			pinctrl-3 = <0x2e>;
			pinctrl-4 = <0x2f>;
			status = "okay";
		};

		apuart3@11005000 {
			cell-index = <0x3>;
			compatible = "mediatek,mt6735-uart";
			reg = <0x11005000 0x1000 0x11000680 0x80 0x11000700 0x80>;
			interrupts = <0x0 0x5e 0x8 0x0 0x6d 0x8 0x0 0x6e 0x8>;
			clock-frequency = <0x18cba80>;
			clock-div = <0x1>;
			clocks = <0x2 0x15>;
			clock-names = "uart3-main";
			pinctrl-names = "uart3_gpio_default", "uart3_rx_set", "uart3_rx_clear", "uart3_tx_set", "uart3_tx_clear";
			pinctrl-0 = <0x30>;
			pinctrl-1 = <0x31>;
			pinctrl-2 = <0x32>;
			pinctrl-3 = <0x33>;
			pinctrl-4 = <0x34>;
			status = "okay";
		};

		pwm@11006000 {
			compatible = "mediatek,pwm";
			reg = <0x11006000 0x1000>;
			interrupts = <0x0 0x4d 0x8>;
			clocks = <0x2 0xa 0x2 0x3 0x2 0x4 0x2 0x5 0x2 0x6 0x2 0x7>;
			clock-names = "PWM-main", "PWM1-main", "PWM2-main", "PWM3-main", "PWM4-main", "PWM5-main";
		};

		devapc_ao@10007000 {
			compatible = "mediatek,devapc_ao";
			reg = <0x10007000 0x1000>;
		};

		i2c@11007000 {
			compatible = "mediatek,mt6735-i2c";
			cell-index = <0x0>;
			reg = <0x11007000 0x1000>;
			interrupts = <0x0 0x54 0x8 0x0 0x63 0x8>;
			def_speed = <0x64>;
			clocks = <0x2 0x18 0x2 0xd>;
			clock-names = "i2c0-main", "i2c0-dma";
			clock-frequency = <0x3520>;
			clock-div = <0x1>;
			#address-cells = <0x1>;
			#size-cells = <0x0>;

			camera_main@2d {
				compatible = "mediatek,camera_main";
				reg = <0x2d>;
				status = "okay";
			};

			camera_main_af@0c {
				compatible = "mediatek,camera_main_af";
				reg = <0xc>;
				status = "okay";
			};

			camera_sub@10 {
				compatible = "mediatek,camera_sub";
				reg = <0x10>;
				status = "okay";
			};
		};

		i2c@11008000 {
			compatible = "mediatek,mt6735-i2c";
			cell-index = <0x1>;
			reg = <0x11008000 0x1000>;
			interrupts = <0x0 0x55 0x8 0x0 0x64 0x8>;
			def_speed = <0x64>;
			clocks = <0x2 0x19 0x2 0xd>;
			clock-names = "i2c1-main", "i2c1-dma";
			clock-frequency = <0x3520>;
			clock-div = <0x1>;
			#address-cells = <0x1>;
			#size-cells = <0x0>;

			cap_touch@38 {
				compatible = "mediatek,cap_touch";
				reg = <0x38>;
				status = "okay";
			};
		};

		spi@1100a000 {
			compatible = "mediatek,mt6735-spi";
			cell-index = <0x0>;
			spi-padmacro = <0x0>;
			reg = <0x1100a000 0x1000>;
			interrupts = <0x0 0x76 0x8>;
			clocks = <0x2 0x1d>;
			clock-names = "spi-main";
			clock-frequency = <0x67f3540>;
			clock-div = <0x1>;
		};

		i2c@11009000 {
			compatible = "mediatek,mt6735-i2c";
			cell-index = <0x2>;
			reg = <0x11009000 0x1000>;
			interrupts = <0x0 0x56 0x8 0x0 0x65 0x8>;
			def_speed = <0x64>;
			clocks = <0x2 0x1a 0x2 0xd>;
			clock-names = "i2c2-main", "i2c2-dma";
			clock-frequency = <0x3520>;
			clock-div = <0x1>;
			#address-cells = <0x1>;
			#size-cells = <0x0>;

			i2c_lcd_bias@3e {
				compatible = "mediatek,i2c_lcd_bias";
				reg = <0x3e>;
				status = "okay";
			};

			msensor@30 {
				compatible = "mediatek,msensor";
				reg = <0x30>;
				status = "okay";
			};

			gyro@68 {
				compatible = "mediatek,gyro";
				reg = <0x68>;
				status = "okay";
			};

			gsensor@15 {
				compatible = "mediatek,gsensor";
				reg = <0x15>;
				status = "okay";
			};

			alsps@49 {
				compatible = "mediatek,alsps";
				reg = <0x49>;
				status = "okay";
			};

			strobe_main@63 {
				compatible = "mediatek,strobe_main";
				reg = <0x63>;
				status = "okay";
			};

			swithing_charger@6a {
				compatible = "mediatek,swithing_charger";
				reg = <0x6a>;
				status = "okay";
				ichg = <0x1f4>;
				aicr = <0x1f4>;
				mivr = <0x1194>;
				ieoc = <0x96>;
				te = <0x1>;
				te-shdn = <0x1>;
				rt9458,irq_gpio = <0xb 0x3 0x0>;
			};

			usb_type_c@4e {
				compatible = "mediatek,usb_type_c";
				reg = <0x4e>;
				status = "okay";
			};
		};

		therm_ctrl@1100b000 {
			compatible = "mediatek,mt6735-therm_ctrl";
			reg = <0x1100b000 0x1000>;
			interrupts = <0x0 0x4e 0x8>;
			clocks = <0x2 0x2>;
			clock-names = "therm-main";
		};

		ptp_fsm@1100b000 {
			compatible = "mediatek,ptp_fsm_v1";
			reg = <0x1100b000 0x1000>;
			interrupts = <0x0 0x7d 0x8>;
		};

		btif@1100c000 {
			compatible = "mediatek,btif";
			reg = <0x1100c000 0x1000>;
			interrupts = <0x0 0x5a 0x8>;
			clocks = <0x2 0x17 0x2 0xd>;
			clock-names = "btifc", "apdmac";
		};

		apuart4@1100D000 {
			cell-index = <0x4>;
			compatible = "mediatek,mt6735-uart";
			reg = <0x1100d000 0x1000 0x11000780 0x80 0x11000800 0x80>;
			interrupts = <0x0 0x5f 0x8 0x0 0x6f 0x8 0x0 0x70 0x8>;
			clock-frequency = <0x18cba80>;
			clock-div = <0x1>;
			clocks = <0x2 0x16>;
			clock-names = "uart4-main";
		};

		i2c@1100f000 {
			compatible = "mediatek,mt6735-i2c";
			cell-index = <0x3>;
			reg = <0x1100f000 0x1000>;
			interrupts = <0x0 0x57 0x8 0x0 0x66 0x8>;
			def_speed = <0x64>;
			clocks = <0x2 0x1b 0x2 0xd>;
			clock-names = "i2c3-main", "i2c3-dma";
			clock-frequency = <0x3520>;
			clock-div = <0x1>;
			#address-cells = <0x1>;
			#size-cells = <0x0>;

			nfc@28 {
				compatible = "mediatek,nfc";
				reg = <0x28>;
				status = "okay";
			};

			ext_buck@6b {
				compatible = "mediatek,ext_buck";
				reg = <0x6b>;
				status = "okay";
			};

			led_ktd2037@30 {
				compatible = "mediatek,led_ktd2037";
				reg = <0x30>;
				status = "okay";
			};
		};

		i2c@11010000 {
			compatible = "mediatek,mt6735-i2c";
			cell-index = <0x4>;
			reg = <0xa7ffd0 0x1000>;
			def_speed = <0x64>;
			clocks = <0x2 0x1b 0x2 0xd>;
			clock-names = "i2c4-main", "i2c4-dma";
			clock-frequency = <0x3520>;
			clock-div = <0x1>;
		};

		usb20@11200000 {
			compatible = "mediatek,mt6735-usb20";
			cell-index = <0x0>;
			reg = <0x11200000 0x10000 0x11210000 0x10000>;
			interrupts = <0x0 0x48 0x8>;
			mode = <0x2>;
			multipoint = <0x1>;
			num_eps = <0x10>;
			clocks = <0x2 0xb>;
			clock-names = "usb0";
			vusb33-supply = <0x35>;
			iddig_gpio = <0x0 0x1>;
			drvvbus_gpio = <0x53 0x2>;
			pinctrl-names = "usb_default", "iddig_irq_init", "drvvbus_init", "drvvbus_low", "drvvbus_high";
			pinctrl-0 = <0x36>;
			pinctrl-1 = <0x37>;
			pinctrl-2 = <0x38>;
			pinctrl-3 = <0x39>;
			pinctrl-4 = <0x3a>;
			status = "okay";
		};

		audiosys@11220000 {
			compatible = "mediatek,mt6735-audiosys";
			reg = <0x11220000 0x10000>;
			#clock-cells = <0x1>;
			linux,phandle = <0x3b>;
			phandle = <0x3b>;
		};

		audio@11220000 {
			compatible = "mediatek,audio";
			reg = <0x11220000 0x10000>;
			interrupts = <0x0 0x90 0x8>;
		};

		mt_soc_dl1_pcm@11220000 {
			compatible = "mediatek,mt-soc-dl1-pcm";
			reg = <0x11220000 0x1000>;
			interrupts = <0x0 0x90 0x8>;
			clocks = <0x3b 0x1 0x3b 0x2 0x3b 0x8 0x3b 0x9 0x3b 0x7 0x3b 0x3 0x3b 0x4 0x3b 0x6 0x3b 0x5 0x3b 0xa 0x19 0x6 0x3 0x19 0x3 0x1a 0x3 0x21 0x3 0x4b 0x3 0x11 0x3 0x12 0x3 0x33 0x3c 0x8 0x3c 0x9 0x3d>;
			clock-names = "aud_afe_clk", "aud_i2s_clk", "aud_dac_clk", "aud_dac_predis_clk", "aud_adc_clk", "aud_apll22m_clk", "aud_apll24m_clk", "aud_apll1_tuner_clk", "aud_apll2_tuner_clk", "aud_tml_clk", "aud_infra_clk", "aud_mux1_clk", "aud_mux2_clk", "top_ad_apll1_clk", "top_whpll_audio_clk", "top_mux_audio", "top_mux_audio_int", "top_sys_pll1_d4", "apmixed_apll1_clk", "apmixed_apll2_clk", "top_clk26m_clk";
			audclk-gpio = <0x8f 0x0>;
			audmiso-gpio = <0x90 0x0>;
			audmosi-gpio = <0x91 0x0>;
			vowclk-gpio = <0x94 0x0>;
			extspkamp-gpio = <0x75 0x0>;
			i2s1clk-gpio = <0x50 0x0>;
			i2s1dat-gpio = <0x4e 0x0>;
			i2s1mclk-gpio = <0x9 0x0>;
			i2s1ws-gpio = <0x4f 0x0>;
			pinctrl-names = "default", "audpmicclk-mode0", "audpmicclk-mode1", "audi2s1-mode0", "audi2s1-mode1", "extamp-pullhigh", "extamp-pulllow", "extamp2-pullhigh", "extamp2-pulllow", "rcvspk-pullhigh", "rcvspk-pulllow";
			pinctrl-0 = <0x3e>;
			pinctrl-1 = <0x3f>;
			pinctrl-2 = <0x40>;
			pinctrl-3 = <0x41>;
			pinctrl-4 = <0x42>;
			pinctrl-5 = <0x43>;
			pinctrl-6 = <0x44>;
			pinctrl-7 = <0x45>;
			pinctrl-8 = <0x46>;
			pinctrl-9 = <0x47>;
			pinctrl-10 = <0x48>;
			status = "okay";
		};

		mfgsys@13000000 {
			compatible = "mediatek,mt6735-mfgsys";
			reg = <0x13000000 0x1000>;
			#clock-cells = <0x1>;
			linux,phandle = <0x49>;
			phandle = <0x49>;
		};

		g3d_config@13000000 {
			compatible = "mediatek,g3d_config";
			reg = <0x13000000 0x1000>;
		};

		mali@13040000 {
			compatible = "arm,malit720", "arm,mali-t72x", "arm,malit7xx", "arm,mali-midgard";
			reg = <0x13040000 0x4000>;
			interrupts = <0x0 0xd4 0x8 0x0 0xd3 0x8 0x0 0xd2 0x8>;
			interrupt-names = "JOB", "MMU", "GPU";
			clock-frequency = <0x1ad27480>;
			clocks = <0x49 0x1 0x1a 0x1 0x13 0x5 0x13 0x4>;
			clock-names = "mfg-main", "mfg-smi-common", "mtcmos-mfg", "mtcmos-display";
		};

		mmsys@14000000 {
			compatible = "mediatek,mt6735-mmsys";
			reg = <0x14000000 0x1000>;
			#clock-cells = <0x1>;
			linux,phandle = <0x1a>;
			phandle = <0x1a>;
		};

		mmsys_config@14000000 {
			compatible = "mediatek,mmsys_config";
			reg = <0x14000000 0x1000>;
			interrupts = <0x0 0xcd 0x8>;
			clocks = <0x1a 0x3>;
			clock-names = "CAM_MDP";
		};

		mdp_rdma@14001000 {
			compatible = "mediatek,mdp_rdma";
			reg = <0x14001000 0x1000>;
			interrupts = <0x0 0xbb 0x8>;
			clocks = <0x1a 0x4>;
			clock-names = "MDP_RDMA";
		};

		mdp_rsz0@14002000 {
			compatible = "mediatek,mdp_rsz0";
			reg = <0x14002000 0x1000>;
			interrupts = <0x0 0xbc 0x8>;
			clocks = <0x1a 0x5>;
			clock-names = "MDP_RSZ0";
		};

		mdp_rsz1@14003000 {
			compatible = "mediatek,mdp_rsz1";
			reg = <0x14003000 0x1000>;
			interrupts = <0x0 0xbd 0x8>;
			clocks = <0x1a 0x6>;
			clock-names = "MDP_RSZ1";
		};

		mdp_wdma@14004000 {
			compatible = "mediatek,mdp_wdma";
			reg = <0x14004000 0x1000>;
			interrupts = <0x0 0xbf 0x8>;
			clocks = <0x1a 0x8>;
			clock-names = "MDP_WDMA";
		};

		mdp_wrot@14005000 {
			compatible = "mediatek,mdp_wrot";
			reg = <0x14005000 0x1000>;
			interrupts = <0x0 0xc0 0x8>;
			clocks = <0x1a 0x9>;
			clock-names = "MDP_WROT";
		};

		mdp_tdshp@14006000 {
			compatible = "mediatek,mdp_tdshp";
			reg = <0x14006000 0x1000>;
			interrupts = <0x0 0xbe 0x8>;
			clocks = <0x1a 0x7>;
			clock-names = "MDP_TDSHP";
		};

		dpi@14012000 {
			compatible = "mediatek,mt6735-dpi";
			reg = <0x14012000 0x1000>;
			interrupts = <0x0 0xcc 0x8>;
		};

		dispsys@14007000 {
			compatible = "mediatek,mt6735-dispsys";
			reg = <0x14007000 0x1000 0x0 0x0 0x14008000 0x1000 0x14009000 0x1000 0x1400a000 0x1000 0x1400b000 0x1000 0x1400c000 0x1000 0x1400d000 0x1000 0x1400e000 0x1000 0x1400f000 0x1000 0x0 0x0 0x1100e000 0x1000 0x0 0x0 0x14014000 0x1000 0x14011000 0x1000 0x14012000 0x1000 0x14000000 0x1000 0x14015000 0x1000 0x14016000 0x1000 0x14017000 0x1000 0x10206000 0x1000 0x10210000 0x1000 0x10211a70 0xc 0x10211974 0xc 0x10211b70 0xc 0x10206044 0xc 0x10206514 0xc 0x10206558 0xc 0x102100a0 0x1000 0x10209270 0x1000 0x10209274 0x1000 0x0 0x0 0x10209000 0x1000>;
			interrupts = <0x0 0xc1 0x8 0x0 0x0 0x8 0x0 0xc2 0x8 0x0 0xc3 0x8 0x0 0xc4 0x8 0x0 0xc5 0x8 0x0 0xc6 0x8 0x0 0xc7 0x8 0x0 0xc8 0x8 0x0 0xc9 0x8 0x0 0x0 0x8 0x0 0x75 0x8 0x0 0x0 0x8 0x0 0xba 0x8 0x0 0xcb 0x8 0x0 0xcc 0x8 0x0 0xcd 0x8 0x0 0xb0 0x8 0x0 0x0 0x8 0x0 0x0 0x8 0x0 0x0 0x8 0x0 0x0 0x8 0x0 0x0 0x8 0x0 0x0 0x8 0x0 0x0 0x8 0x0 0x0 0x8 0x0 0x0 0x8 0x0 0x0 0x8>;
			clocks = <0x1a 0x1 0x1a 0x2 0x1a 0xb 0x1a 0xc 0x1a 0xd 0x1a 0xe 0x1a 0xf 0x1a 0x10 0x1a 0x11 0x1a 0x12 0x1a 0x13 0x1a 0x14 0x1a 0x15 0x1a 0x16 0x1a 0x17 0x2 0x1 0x3 0x16 0x3c 0x7 0x3 0x3c 0x3 0x3d 0x3 0x3e 0x3 0x4d 0x3 0x1d 0x3 0x45 0x3 0x3a 0x3 0x22 0x13 0x4>;
			clock-names = "DISP0_SMI_COMMON", "DISP0_SMI_LARB0", "DISP0_DISP_OVL0", "DISP0_DISP_RDMA0", "DISP0_DISP_RDMA1", "DISP0_DISP_WDMA0", "DISP0_DISP_COLOR", "DISP0_DISP_CCORR", "DISP0_DISP_AAL", "DISP0_DISP_GAMMA", "DISP0_DISP_DITHER", "DISP1_DSI_ENGINE", "DISP1_DSI_DIGITAL", "DISP1_DPI_ENGINE", "DISP1_DPI_PIXEL", "DISP_PWM", "MUX_DPI0", "TVDPLL", "TVDPLL_CK", "TVDPLL_D2", "TVDPLL_D4", "DPI_CK", "MUX_DISPPWM", "UNIVPLL2_D4", "SYSPLL4_D2_D8", "AD_SYS_26M_CK", "DISP_MTCMOS_CLK";
		};

		mhl@0 {
			compatible = "mediatek,extd_dev";
		};

		lcm_mode {
			compatible = "mediatek,lcm_mode";
			pinctrl-names = "default", "lcm_mode_00", "lcm_mode_01", "lcm_mode_02", "lcm_mode_03", "lcm_mode_04", "lcm_mode_05", "lcm_mode_06", "lcm_mode_07";
			pinctrl-0 = <0x4a>;
			pinctrl-1 = <0x4b>;
			pinctrl-2 = <0x4c>;
			pinctrl-3 = <0x4d>;
			pinctrl-4 = <0x4e>;
			pinctrl-5 = <0x4f>;
			pinctrl-6 = <0x50>;
			pinctrl-7 = <0x51>;
			pinctrl-8 = <0x52>;
			lcm_power_gpio = <0xb 0x50 0x0>;
			status = "okay";
		};

		smi_larb0@14015000 {
			compatible = "mediatek,smi_larb0";
			reg = <0x14015000 0x1000>;
		};

		smi_common@14016000 {
			compatible = "mediatek,smi_common";
			reg = <0x14016000 0x1000 0x14015000 0x1000 0x16010000 0x1000 0x15001000 0x1000 0x17001000 0x1000>;
			clocks = <0x1a 0x1 0x1a 0x2 0x1c 0x1 0x1b 0x1 0x1b 0x2 0x1d 0x1 0x1d 0x2 0x13 0x8 0x13 0x7 0x13 0x6 0x13 0x4>;
			clock-names = "smi-common", "smi-larb0", "img-larb2", "vdec0-vdec", "vdec1-larb", "venc-larb", "venc-venc", "mtcmos-ven", "mtcmos-vde", "mtcmos-isp", "mtcmos-dis";
		};

		met_smi@14016000 {
			compatible = "mediatek,met_smi";
			reg = <0x14016000 0x1000 0x14015000 0x1000 0x16010000 0x1000 0x15001000 0x1000 0x17001000 0x1000>;
			clocks = <0x1a 0x1 0x1a 0x2 0x1c 0x1 0x1b 0x1 0x1b 0x2 0x1d 0x1 0x1d 0x2>;
			clock-names = "smi-common", "smi-larb0", "img-larb2", "vdec0-vdec", "vdec1-larb", "venc-larb", "venc-venc";
		};

		imgsys@15000000 {
			compatible = "mediatek,mt6735-imgsys";
			reg = <0x15000000 0x1000>;
			#clock-cells = <0x1>;
			linux,phandle = <0x1c>;
			phandle = <0x1c>;
		};

		ispsys@15000000 {
			compatible = "mediatek,mt6735-ispsys";
			reg = <0x15004000 0x9000 0x1500d000 0x1000 0x15000000 0x10000 0x10215000 0x3000 0x10211000 0x1000>;
			interrupts = <0x0 0xb7 0x8 0x0 0xb8 0x8 0x0 0xb9 0x8 0x0 0xce 0x8 0x0 0xcf 0x8>;
			clocks = <0x13 0x4 0x13 0x6 0x1a 0x1 0x1c 0x2 0x1c 0x3 0x1c 0x4 0x1c 0x5 0x1c 0x6 0x1c 0x1>;
			clock-names = "CG_SCP_SYS_DIS", "CG_SCP_SYS_ISP", "CG_DISP0_SMI_COMMON", "CG_IMAGE_CAM_SMI", "CG_IMAGE_CAM_CAM", "CG_IMAGE_SEN_TG", "CG_IMAGE_SEN_CAM", "CG_IMAGE_CAM_SV", "CG_IMAGE_LARB2_SMI";
		};

		smi_larb2@15001000 {
			compatible = "mediatek,smi_larb2";
			reg = <0x15001000 0x1000>;
			interrupts = <0x0 0xb2 0x8>;
		};

		kd_camera_hw1@15008000 {
			compatible = "mediatek,camera_hw";
			reg = <0x15008000 0x1000>;
			vcama-supply = <0x53>;
			vcamd-supply = <0x54>;
			vcamaf-supply = <0x55>;
			vcamio-supply = <0x56>;
			clocks = <0x3 0x8 0x3 0x3f 0x3 0x44>;
			clock-names = "TOP_CAMTG_SEL", "TOP_UNIVPLL_D26", "TOP_UNIVPLL2_D2";
			vcama_main2-supply = <0x53>;
			vcama_sub-supply = <0x53>;
			vcamaf_main2-supply = <0x55>;
			vcamaf_sub-supply = <0x55>;
			vcamd_main2-supply = <0x54>;
			vcamd_sub-supply = <0x54>;
			vcamio_main2-supply = <0x56>;
			vcamio_sub-supply = <0x56>;
			status = "okay";
			pinctrl-names = "default", "cam0_rst0", "cam0_rst1", "cam1_rst0", "cam1_rst1";
			pinctrl-0 = <0x57>;
			pinctrl-1 = <0x58>;
			pinctrl-2 = <0x59>;
			pinctrl-3 = <0x5a>;
			pinctrl-4 = <0x5b>;
		};

		kd_camera_hw2@15008000 {
			compatible = "mediatek,camera_hw2";
			reg = <0x15008000 0x1000>;
		};

		fdvt@1500b000 {
			compatible = "mediatek,fdvt";
			reg = <0x1500b000 0x1000>;
			interrupts = <0x0 0xd0 0x8>;
			clocks = <0x13 0x4 0x13 0x6 0x1a 0x1 0x1c 0x8>;
			clock-names = "FD-SCP_SYS_DIS", "FD-SCP_SYS_ISP", "FD-MM_DISP0_SMI_COMMON", "FD-IMG_IMAGE_FD";
		};

		vdecsys@16000000 {
			compatible = "mediatek,mt6735-vdecsys";
			reg = <0x16000000 0x1000>;
			interrupts = <0x0 0xb3 0x8>;
			#clock-cells = <0x1>;
			linux,phandle = <0x1b>;
			phandle = <0x1b>;
		};

		c2k_sdio@0 {
			compatible = "mediatek,mt6735-c2k_sdio";
			interrupts = <0x0 0xe6 0x8>;
		};

		vdec_gcon@16000000 {
			compatible = "mediatek,mt6735-vdec_gcon";
			reg = <0x16000000 0x1000>;
			interrupts = <0x0 0xb3 0x8>;
			clocks = <0x1a 0x1 0x1b 0x1 0x1b 0x2 0x1d 0x2 0x1d 0x1 0x3 0x6 0x3 0x32 0x3 0x33 0x13 0x7 0x13 0x8 0x13 0x4>;
			clock-names = "MT_CG_DISP0_SMI_COMMON", "MT_CG_VDEC0_VDEC", "MT_CG_VDEC1_LARB", "MT_CG_VENC_VENC", "MT_CG_VENC_LARB", "MT_CG_TOP_MUX_VDEC", "MT_CG_TOP_SYSPLL1_D2", "MT_CG_TOP_SYSPLL1_D4", "MT_SCP_SYS_VDE", "MT_SCP_SYS_VEN", "MT_SCP_SYS_DIS";
		};

		smi_larb1@16010000 {
			compatible = "mediatek,smi_larb1";
			reg = <0x16010000 0x1000>;
			interrupts = <0x0 0xb1 0x8>;
		};

		vdec@16020000 {
			compatible = "mediatek,mt6735-vdec";
			reg = <0x16020000 0x10000>;
			interrupts = <0x0 0xb3 0x8>;
		};

		vencsys@17000000 {
			compatible = "mediatek,mt6735-vencsys";
			reg = <0x17000000 0x1000>;
			interrupts = <0x0 0xb4 0x8>;
			#clock-cells = <0x1>;
			linux,phandle = <0x1d>;
			phandle = <0x1d>;
		};

		venc_gcon@17000000 {
			compatible = "mediatek,mt6735-venc_gcon";
			reg = <0x17000000 0x1000>;
			interrupts = <0x0 0xb4 0x8>;
		};

		smi_larb3@17001000 {
			compatible = "mediatek,smi_larb3";
			reg = <0x17001000 0x1000>;
			interrupts = <0x0 0xca 0x8>;
		};

		venc@17002000 {
			compatible = "mediatek,mt6735-venc";
			reg = <0x17002000 0x1000>;
			interrupts = <0x0 0xb4 0x8>;
		};

		jpgenc@17003000 {
			compatible = "mediatek,jpgenc";
			reg = <0x17003000 0x1000>;
			interrupts = <0x0 0xb5 0x8>;
			clocks = <0x13 0x4 0x1a 0x1 0x13 0x8 0x1d 0x1 0x1d 0x3>;
			clock-names = "disp-mtcmos", "disp-smi", "venc-mtcmos", "venc-larb", "venc-jpgenc";
		};

		jpgdec@17004000 {
			compatible = "mediatek,jpgdec";
			reg = <0x17004000 0x1000>;
			interrupts = <0x0 0xd1 0x8>;
			clocks = <0x13 0x4 0x1a 0x1 0x13 0x8 0x1d 0x1 0x1d 0x4>;
			clock-names = "disp-mtcmos", "disp-smi", "venc-mtcmos", "venc-larb", "venc-jpgdec";
		};

		consys@18070000 {
			compatible = "mediatek,mt6735-consys";
			reg = <0x18070000 0x200 0x10212000 0x100 0x10000000 0x2000 0x10006000 0x1000>;
			interrupts = <0x0 0xe3 0x8 0x0 0xe1 0x8>;
			clocks = <0x13 0x3 0x19 0xb>;
			clock-names = "conn", "bus";
			vcn18-supply = <0x5c>;
			vcn28-supply = <0x5d>;
			vcn33_bt-supply = <0x5e>;
			vcn33_wifi-supply = <0x5f>;
			pinctrl-names = "default", "gps_lna_state_init", "gps_lna_state_oh", "gps_lna_state_ol";
			pinctrl-0 = <0x60>;
			pinctrl-1 = <0x61>;
			pinctrl-2 = <0x62>;
			pinctrl-3 = <0x63>;
			status = "okay";
		};

		wifi@180F0000 {
			compatible = "mediatek,wifi";
			reg = <0x180f0000 0x5c>;
			interrupts = <0x0 0xe2 0x8>;
			clocks = <0x2 0xd>;
			clock-names = "wifi-dma";
		};

		mdc2k@3a00b01c {
			compatible = "mediatek,mdc2k";
			reg = <0x3a00b01c 0x10 0x1021c800 0x300 0x1021d800 0x300>;
			interrupts = <0x0 0xe5 0x2>;
			clocks = <0x13 0x2>;
			clock-names = "scp-sys-md2-main";
		};

		mtkfb@7e000000 {
			compatible = "mediatek,mtkfb";
			reg = <0x7e000000 0x1000000>;
		};

		mt_soc_ul1_pcm {
			compatible = "mediatek,mt_soc_pcm_capture";
		};

		mt_soc_voice_md1 {
			compatible = "mediatek,mt_soc_pcm_voice_md1";
		};

		mt_soc_hdmi_pcm {
			compatible = "mediatek,mt_soc_pcm_hdmi";
		};

		mt_soc_uldlloopback_pcm {
			compatible = "mediatek,mt_soc_pcm_uldlloopback";
		};

		mt_soc_i2s0_pcm {
			compatible = "mediatek,mt_soc_pcm_dl1_i2s0";
		};

		mt_soc_mrgrx_pcm {
			compatible = "mediatek,mt_soc_pcm_mrgrx";
		};

		mt_soc_mrgrx_awb_pcm {
			compatible = "mediatek,mt_soc_pcm_mrgrx_awb";
		};

		mt_soc_fm_i2s_pcm {
			compatible = "mediatek,mt_soc_pcm_fm_i2s";
		};

		mt_soc_fm_i2s_awb_pcm {
			compatible = "mediatek,mt_soc_pcm_fm_i2s_awb";
		};

		mt_soc_i2s0dl1_pcm {
			compatible = "mediatek,mt_soc_pcm_dl1_i2s0Dl1";
		};

		mt_soc_dl1_awb_pcm {
			compatible = "mediatek,mt_soc_pcm_dl1_awb";
		};

		mt_soc_voice_md1_bt {
			compatible = "mediatek,mt_soc_pcm_voice_md1_bt";
		};

		mt_soc_voip_bt_out {
			compatible = "mediatek,mt_soc_pcm_dl1_bt";
		};

		mt_soc_voip_bt_in {
			compatible = "mediatek,mt_soc_pcm_bt_dai";
		};

		mt_soc_tdmrx_pcm {
			compatible = "mediatek,mt_soc_tdm_capture";
		};

		mt_soc_fm_mrgtx_pcm {
			compatible = "mediatek,mt_soc_pcm_fmtx";
		};

		mt_soc_ul2_pcm {
			compatible = "mediatek,mt_soc_pcm_capture2";
		};

		mt_soc_i2s0_awb_pcm {
			compatible = "mediatek,mt_soc_pcm_i2s0_awb";
		};

		mt_soc_voice_md2 {
			compatible = "mediatek,mt_soc_pcm_voice_md2";
		};

		mt_soc_routing_pcm {
			compatible = "mediatek,mt_soc_pcm_routing";
			i2s1clk-gpio = <0x7 0x6>;
			i2s1dat-gpio = <0x5 0x6>;
			i2s1mclk-gpio = <0x9 0x6>;
			i2s1ws-gpio = <0x6 0x6>;
		};

		mt_soc_voice_md2_bt {
			compatible = "mediatek,mt_soc_pcm_voice_md2_bt";
		};

		mt_soc_hp_impedance_pcm {
			compatible = "mediatek,Mt_soc_pcm_hp_impedance";
		};

		mt_soc_codec_name {
			compatible = "mediatek,mt_soc_codec_63xx";
		};

		mt_soc_dummy_pcm {
			compatible = "mediatek,mt_soc_pcm_dummy";
		};

		mt_soc_codec_dummy_name {
			compatible = "mediatek,mt_soc_codec_dummy";
		};

		mt_soc_routing_dai_name {
			compatible = "mediatek,mt_soc_dai_routing";
		};

		mt_soc_dai_name {
			compatible = "mediatek,mt_soc_dai_stub";
		};

		mt_soc_offload_gdma {
			compatible = "mediatek,mt_soc_pcm_offload_gdma";
		};

		mt_soc_dl2_pcm {
			compatible = "mediatek,mt_soc_pcm_dl2";
		};

		rgb_ktd2037 {
			compatible = "mediatek,ktd2037-platform";
		};

		touch {
			compatible = "mediatek,mt6735-touch";
			vtouch-supply = <0x64>;
			interrupt-parent = <0xc>;
			interrupts = <0xa 0x2>;
			debounce = <0xa 0x0>;
			status = "okay";
			tpd-resolution = <0x438 0x780>;
			use-tpd-button = <0x0>;
			tpd-key-num = <0x3>;
			tpd-key-local = <0x8b 0xac 0x9e 0x0>;
			tpd-key-dim-local = <0x5a 0x373 0x64 0x28 0xe6 0x373 0x64 0x28 0x172 0x373 0x64 0x28 0x0 0x0 0x0 0x0>;
			tpd-max-touch-num = <0x5>;
			tpd-filter-enable = <0x0>;
			tpd-filter-pixel-density = <0xba>;
			tpd-filter-custom-prameters = <0x0 0x0 0x0 0x0 0x0 0x0 0x0 0x0 0x0 0x0 0x0 0x0>;
			tpd-filter-custom-speed = <0x0 0x0 0x0>;
			pinctrl-names = "default", "state_eint_as_int", "state_eint_output0", "state_eint_output1", "state_rst_output0", "state_rst_output1", "state_eint_input1";
			pinctrl-0 = <0x65>;
			pinctrl-1 = <0x66>;
			pinctrl-2 = <0x67>;
			pinctrl-3 = <0x68>;
			pinctrl-4 = <0x69>;
			pinctrl-5 = <0x6a>;
			pinctrl-6 = <0x6b>;
		};

		hall_1@2 {
			compatible = "mediatek,mt6735-hall_1";
			interrupt-parent = <0xc>;
			interrupts = <0x2 0x8>;
			debounce = <0x2 0x0>;
			status = "okay";
		};

		accdet {
			compatible = "mediatek,mt6735-accdet";
			interrupt-parent = <0xc>;
			interrupts = <0x6 0x8>;
			debounce = <0x6 0x3e800>;
			status = "okay";
			accdet-mic-vol = <0x7>;
			headset-mode-setting = <0x500 0x200 0x1 0x1f0 0x800 0x800 0x20>;
			accdet-plugout-debounce = <0x14>;
			accdet-mic-mode = <0x1>;
			headset-three-key-threshold = <0x0 0x50 0xdc 0x1f4>;
			headset-four-key-threshold = <0x0 0x3c 0x6e 0xaa 0x140>;
			pinctrl-names = "default", "state_eint_as_int";
			pinctrl-0 = <0x65>;
			pinctrl-1 = <0x66>;
		};

		nfc {
			compatible = "mediatek,nfc-gpio-v2";
			ven-gpio = <0xb>;
			firm-gpio = <0xc>;
			irq-gpio = <0x7>;
			interrupt-parent = <0xc>;
			interrupts = <0x7 0x1>;
			debounce = <0x7 0x0>;
			status = "okay";
			pinctrl-names = "default", "ven_high", "ven_low", "rst_high", "rst_low", "eint_high", "eint_low", "irq_init";
			pinctrl-0 = <0x60>;
			pinctrl-1 = <0x6c>;
			pinctrl-2 = <0x6d>;
			pinctrl-3 = <0x6e>;
			pinctrl-4 = <0x6f>;
			pinctrl-5 = <0x70>;
			pinctrl-6 = <0x71>;
			pinctrl-7 = <0x72>;
		};

		gps {
			compatible = "mediatek,gps";
		};

		simswitch {
			compatible = "mediatek,sim_switch";
			pinctrl-names = "default", "hot_plug_mode1", "hot_plug_mode2", "two_sims_bound_to_md1", "sim1_md3_sim2_md1";
			pinctrl-0 = <0x73>;
			pinctrl-1 = <0x74>;
			pinctrl-2 = <0x75>;
			pinctrl-3 = <0x76>;
			pinctrl-4 = <0x77>;
		};

		ccci_off {
			compatible = "mediatek,ccci_off";
			clocks = <0x13 0x1>;
			clock-names = "scp-sys-md1-main";
		};

		pmu {
			compatible = "arm,armv8-pmuv3";
			interrupts = <0x0 0x8 0x8 0x0 0x9 0x8 0x0 0xa 0x8 0x0 0xb 0x8>;
			interrupt-affinity = <0xf 0x10 0x11 0x12>;
		};

		timer {
			compatible = "arm,armv8-timer";
			interrupts = <0x1 0xd 0x8 0x1 0xe 0x8 0x1 0xb 0x8 0x1 0xa 0x8>;
			clock-frequency = <0xc65d40>;
		};

		mt_pmic_regulator {
			compatible = "mediatek,mt_pmic";

			buck_regulators {
				compatible = "mediatek,mt_pmic_buck_regulators";

				buck_vpa {
					regulator-name = "vpa";
					regulator-min-microvolt = <0x7a120>;
					regulator-max-microvolt = <0x37b1d0>;
					regulator-ramp-delay = <0xc350>;
					regulator-enable-ramp-delay = <0xb4>;
				};

				buck_vproc {
					regulator-name = "vproc";
					regulator-min-microvolt = <0x927c0>;
					regulator-max-microvolt = <0x154456>;
					regulator-ramp-delay = <0x186a>;
					regulator-enable-ramp-delay = <0xb4>;
					regulator-always-on;
					regulator-boot-on;
				};

				buck_vcore1 {
					regulator-name = "vcore1";
					regulator-min-microvolt = <0x927c0>;
					regulator-max-microvolt = <0x154456>;
					regulator-ramp-delay = <0x186a>;
					regulator-enable-ramp-delay = <0xb4>;
					regulator-always-on;
					regulator-boot-on;
				};

				buck_vsys22 {
					regulator-name = "vsys22";
					regulator-min-microvolt = <0x124f80>;
					regulator-max-microvolt = <0x1e6c16>;
					regulator-ramp-delay = <0x186a>;
					regulator-enable-ramp-delay = <0xb4>;
					regulator-always-on;
					regulator-boot-on;
				};

				buck_vlte {
					regulator-name = "vlte";
					regulator-min-microvolt = <0x927c0>;
					regulator-max-microvolt = <0x154456>;
					regulator-ramp-delay = <0x186a>;
					regulator-enable-ramp-delay = <0xb4>;
					regulator-always-on;
					regulator-boot-on;
				};
			};

			ldo_regulators {
				compatible = "mediatek,mt_pmic_ldo_regulators";

				ldo_vaux18 {
					regulator-name = "vaux18";
					regulator-min-microvolt = <0x1b7740>;
					regulator-max-microvolt = <0x1b7740>;
					regulator-enable-ramp-delay = <0x108>;
					regulator-boot-on;
					linux,phandle = <0x78>;
					phandle = <0x78>;
				};

				ldo_vtcxo_0 {
					regulator-name = "vtcxo_0";
					regulator-min-microvolt = <0x2ab980>;
					regulator-max-microvolt = <0x2ab980>;
					regulator-enable-ramp-delay = <0x6e>;
					regulator-boot-on;
					linux,phandle = <0x79>;
					phandle = <0x79>;
				};

				ldo_vtcxo_1 {
					regulator-name = "vtcxo_1";
					regulator-min-microvolt = <0x2ab980>;
					regulator-max-microvolt = <0x2ab980>;
					regulator-enable-ramp-delay = <0x6e>;
					linux,phandle = <0x7a>;
					phandle = <0x7a>;
				};

				ldo_vaud28 {
					regulator-name = "vaud28";
					regulator-min-microvolt = <0x2ab980>;
					regulator-max-microvolt = <0x2ab980>;
					regulator-enable-ramp-delay = <0x108>;
					regulator-boot-on;
					linux,phandle = <0x7b>;
					phandle = <0x7b>;
				};

				ldo_vcn28 {
					regulator-name = "vcn28";
					regulator-min-microvolt = <0x2ab980>;
					regulator-max-microvolt = <0x2ab980>;
					regulator-enable-ramp-delay = <0x108>;
					linux,phandle = <0x5d>;
					phandle = <0x5d>;
				};

				ldo_vcama {
					regulator-name = "vcama";
					regulator-min-microvolt = <0x16e360>;
					regulator-max-microvolt = <0x2ab980>;
					regulator-enable-ramp-delay = <0x108>;
					regulator-default-on = <0x0>;
					status = "okay";
					linux,phandle = <0x53>;
					phandle = <0x53>;
				};

				ldo_vcn33_bt {
					regulator-name = "vcn33_bt";
					regulator-min-microvolt = <0x325aa0>;
					regulator-max-microvolt = <0x36ee80>;
					regulator-enable-ramp-delay = <0x108>;
					linux,phandle = <0x5e>;
					phandle = <0x5e>;
				};

				ldo_vcn33_wifi {
					regulator-name = "vcn33_wifi";
					regulator-min-microvolt = <0x325aa0>;
					regulator-max-microvolt = <0x36ee80>;
					regulator-enable-ramp-delay = <0x108>;
					linux,phandle = <0x5f>;
					phandle = <0x5f>;
				};

				ldo_vusb33 {
					regulator-name = "vusb33";
					regulator-min-microvolt = <0x325aa0>;
					regulator-max-microvolt = <0x325aa0>;
					regulator-enable-ramp-delay = <0x108>;
					regulator-boot-on;
					linux,phandle = <0x35>;
					phandle = <0x35>;
				};

				ldo_vefuse {
					regulator-name = "vefuse";
					regulator-min-microvolt = <0x1b7740>;
					regulator-max-microvolt = <0x2191c0>;
					regulator-enable-ramp-delay = <0x108>;
					linux,phandle = <0x7c>;
					phandle = <0x7c>;
				};

				ldo_vsim1 {
					regulator-name = "vsim1";
					regulator-min-microvolt = <0x19f0a0>;
					regulator-max-microvolt = <0x200b20>;
					regulator-enable-ramp-delay = <0x108>;
					regulator-default-on = <0x0>;
					status = "okay";
					linux,phandle = <0x7d>;
					phandle = <0x7d>;
				};

				ldo_vsim2 {
					regulator-name = "vsim2";
					regulator-min-microvolt = <0x19f0a0>;
					regulator-max-microvolt = <0x200b20>;
					regulator-enable-ramp-delay = <0x108>;
					regulator-default-on = <0x0>;
					status = "okay";
					linux,phandle = <0x7e>;
					phandle = <0x7e>;
				};

				ldo_vemc_3v3 {
					regulator-name = "vemc_3v3";
					regulator-min-microvolt = <0x1b7740>;
					regulator-max-microvolt = <0x325aa0>;
					regulator-enable-ramp-delay = <0x108>;
					regulator-boot-on;
					linux,phandle = <0x7f>;
					phandle = <0x7f>;
				};

				ldo_vmch {
					regulator-name = "vmch";
					regulator-min-microvolt = <0x2c4020>;
					regulator-max-microvolt = <0x325aa0>;
					regulator-enable-ramp-delay = <0x2c>;
					linux,phandle = <0x80>;
					phandle = <0x80>;
				};

				ldo_vtref {
					regulator-name = "vtref";
					regulator-min-microvolt = <0x1b7740>;
					regulator-max-microvolt = <0x1b7740>;
					regulator-enable-ramp-delay = <0xf0>;
					linux,phandle = <0x81>;
					phandle = <0x81>;
				};

				ldo_vmc {
					regulator-name = "vmc";
					regulator-min-microvolt = <0x1b7740>;
					regulator-max-microvolt = <0x325aa0>;
					regulator-enable-ramp-delay = <0x2c>;
					linux,phandle = <0x82>;
					phandle = <0x82>;
				};

				ldo_vcamaf {
					regulator-name = "vcamaf";
					regulator-min-microvolt = <0x124f80>;
					regulator-max-microvolt = <0x325aa0>;
					regulator-enable-ramp-delay = <0x108>;
					regulator-default-on = <0x0>;
					status = "okay";
					linux,phandle = <0x55>;
					phandle = <0x55>;
				};

				ldo_vio28 {
					regulator-name = "vio28";
					regulator-min-microvolt = <0x2ab980>;
					regulator-max-microvolt = <0x2ab980>;
					regulator-enable-ramp-delay = <0x108>;
					regulator-boot-on;
					linux,phandle = <0x83>;
					phandle = <0x83>;
				};

				ldo_vgp1 {
					regulator-name = "vgp1";
					regulator-min-microvolt = <0x124f80>;
					regulator-max-microvolt = <0x325aa0>;
					regulator-enable-ramp-delay = <0x108>;
					regulator-default-on = <0x0>;
					status = "okay";
					linux,phandle = <0x64>;
					phandle = <0x64>;
				};

				ldo_vibr {
					regulator-name = "vibr";
					regulator-min-microvolt = <0x124f80>;
					regulator-max-microvolt = <0x325aa0>;
					regulator-enable-ramp-delay = <0x2c>;
					regulator-default-on = <0x0>;
					status = "okay";
					linux,phandle = <0x84>;
					phandle = <0x84>;
				};

				ldo_vcamd {
					regulator-name = "vcamd";
					regulator-min-microvolt = <0xdbba0>;
					regulator-max-microvolt = <0x16e360>;
					regulator-enable-ramp-delay = <0x108>;
					regulator-default-on = <0x0>;
					status = "okay";
					linux,phandle = <0x54>;
					phandle = <0x54>;
				};

				ldo_vrf18_0 {
					regulator-name = "vrf18_0";
					regulator-min-microvolt = <0x1bd8e8>;
					regulator-max-microvolt = <0x1bd8e8>;
					regulator-enable-ramp-delay = <0xdc>;
					linux,phandle = <0x85>;
					phandle = <0x85>;
				};

				ldo_vrf18_1 {
					regulator-name = "vrf18_1";
					regulator-min-microvolt = <0x124f80>;
					regulator-max-microvolt = <0x1bd8e8>;
					regulator-enable-ramp-delay = <0xdc>;
					linux,phandle = <0x86>;
					phandle = <0x86>;
				};

				ldo_vio18 {
					regulator-name = "vio18";
					regulator-min-microvolt = <0x1b7740>;
					regulator-max-microvolt = <0x1b7740>;
					regulator-enable-ramp-delay = <0x108>;
					regulator-boot-on;
					linux,phandle = <0x87>;
					phandle = <0x87>;
				};

				ldo_vcn18 {
					regulator-name = "vcn18";
					regulator-min-microvolt = <0x1b7740>;
					regulator-max-microvolt = <0x1b7740>;
					regulator-enable-ramp-delay = <0x2c>;
					linux,phandle = <0x5c>;
					phandle = <0x5c>;
				};

				ldo_vcamio {
					regulator-name = "vcamio";
					regulator-min-microvolt = <0x124f80>;
					regulator-max-microvolt = <0x1b7740>;
					regulator-enable-ramp-delay = <0xdc>;
					regulator-default-on = <0x0>;
					status = "okay";
					linux,phandle = <0x56>;
					phandle = <0x56>;
				};

				ldo_vsram {
					regulator-name = "vsram";
					regulator-min-microvolt = <0xaae60>;
					regulator-max-microvolt = <0x16caf6>;
					regulator-enable-ramp-delay = <0xdc>;
					regulator-ramp-delay = <0x186a>;
					regulator-boot-on;
					linux,phandle = <0x88>;
					phandle = <0x88>;
				};

				ldo_vm {
					regulator-name = "vm";
					regulator-min-microvolt = <0x12ebc0>;
					regulator-max-microvolt = <0x177fa0>;
					regulator-enable-ramp-delay = <0x108>;
					regulator-boot-on;
					linux,phandle = <0x89>;
					phandle = <0x89>;
				};
			};

			regulators_supply {
				compatible = "mediatek,mt_pmic_regulator_supply";
				vaux18-supply = <0x78>;
				vtcxo_0-supply = <0x79>;
				vtcxo_1-supply = <0x7a>;
				vaud28-supply = <0x7b>;
				vefuse-supply = <0x7c>;
				vsim1-supply = <0x7d>;
				vsim2-supply = <0x7e>;
				vemc_3v3-supply = <0x7f>;
				vmch-supply = <0x80>;
				vtref-supply = <0x81>;
				vmc-supply = <0x82>;
				vio28-supply = <0x83>;
				vibr-supply = <0x84>;
				vrf18_0-supply = <0x85>;
				vrf18_1-supply = <0x86>;
				vio18-supply = <0x87>;
				vsram-supply = <0x88>;
				vm-supply = <0x89>;
			};
		};

		btcvsd@10000000 {
			compatible = "mediatek,audio_bt_cvsd";
			offset = <0x700 0x800 0xfd0 0xfd4 0xfd8>;
			reg = <0x10000000 0x1000 0x18000000 0x10000 0x18080000 0x8000>;
			interrupts = <0x0 0xe4 0x8>;
		};

		bat_meter {
			compatible = "mediatek,bat_meter";
			r_bat_sense = <0x4>;
			r_i_sense = <0x4>;
			r_charger_1 = <0x14a>;
			r_charger_2 = <0x27>;
			temperature_t0 = <0x6e>;
			temperature_t1 = <0x0>;
			temperature_t2 = <0x19>;
			temperature_t3 = <0x32>;
			temperature_t = <0xff>;
			fg_meter_resistance = <0x0>;
			q_max_pos_50 = <0x5b7>;
			q_max_pos_25 = <0x59d>;
			q_max_pos_0 = <0x4c4>;
			q_max_neg_10 = <0x471>;
			q_max_pos_50_h_current = <0x5e7>;
			q_max_pos_25_h_current = <0x5b6>;
			q_max_pos_0_h_current = <0x332>;
			q_max_neg_10_h_current = <0x95>;
			oam_d5 = <0x1>;
			change_tracking_point = <0x1>;
			cust_tracking_point = <0x0>;
			cust_r_sense = <0x44>;
			cust_hw_cc = <0x0>;
			aging_tuning_value = <0x67>;
			cust_r_fg_offset = <0x0>;
			ocv_board_compesate = <0x0>;
			r_fg_board_base = <0x3e8>;
			r_fg_board_slope = <0x3e8>;
			car_tune_value = <0x68>;
			current_detect_r_fg = <0xa>;
			minerroroffset = <0x3e8>;
			fg_vbat_average_size = <0x12>;
			r_fg_value = <0xa>;
			cust_poweron_delta_capacity_tolrance = <0x28>;
			cust_poweron_low_capacity_tolrance = <0x5>;
			cust_poweron_max_vbat_tolrance = <0x5a>;
			cust_poweron_delta_vbat_tolrance = <0x1e>;
			cust_poweron_delta_hw_sw_ocv_capacity_tolrance = <0xa>;
			fixed_tbat_25 = <0x0>;
			vbat_normal_wakeup = <0xe10>;
			vbat_low_power_wakeup = <0xdac>;
			normal_wakeup_period = <0x1518>;
			low_power_wakeup_period = <0x12c>;
			close_poweroff_wakeup_period = <0x1e>;
			rbat_pull_up_r = <0x4204>;
			rbat_pull_up_volt = <0x708>;
			batt_temperature_table_num = <0x11>;
			batt_temperature_table = <0xffffffec 0x10a8d 0xfffffff1 0xd192 0xfffffff6 0xa60a 0xfffffffb 0x8464 0x0 0x6a53 0x5 0x5605 0xa 0x4606 0xf 0x3952 0x14 0x2f31 0x19 0x2710 0x1e 0x207b 0x23 0x1b24 0x28 0x16ca 0x2d 0x1335 0x32 0x1041 0x37 0xdcf 0x3c 0xbc6>;
			battery_profile_t0_num = <0x64>;
			battery_profile_t0 = <0x0 0xfd0 0x2 0xfa8 0x4 0xf95 0x5 0xf89 0x7 0xf7e 0x9 0xf78 0xb 0xf6e 0xc 0xf6a 0xe 0xf62 0x10 0xf5c 0x12 0xf56 0x13 0xf4e 0x15 0xf46 0x17 0xf3d 0x19 0xf36 0x1a 0xf2d 0x1c 0xf22 0x1e 0xf1a 0x20 0xf10 0x21 0xf06 0x23 0xefe 0x25 0xef6 0x27 0xeef 0x28 0xee9 0x2a 0xee6 0x2c 0xee0 0x2e 0xede 0x2f 0xedb 0x31 0xed9 0x33 0xed6 0x35 0xed3 0x36 0xed4 0x38 0xed3 0x3a 0xed0 0x3c 0xed0 0x3d 0xece 0x3f 0xecd 0x41 0xecb 0x43 0xec9 0x44 0xec7 0x46 0xec5 0x48 0xec0 0x4a 0xebc 0x4b 0xeb7 0x4d 0xeb3 0x4f 0xeae 0x51 0xea7 0x52 0xe9e 0x54 0xe96 0x56 0xe8d 0x58 0xe87 0x5a 0xe83 0x5b 0xe80 0x5d 0xe7b 0x5f 0xe76 0x61 0xe70 0x62 0xe5e 0x64 0xe3f 0x65 0xe1c 0x66 0xdf7 0x67 0xdd1 0x67 0xdae 0x68 0xd90 0x68 0xd73 0x68 0xd5b 0x69 0xd43 0x69 0xd2d 0x69 0xd1d 0x69 0xd0d 0x69 0xd00 0x69 0xcf5 0x69 0xceb 0x69 0xce4 0x69 0xcdd 0x69 0xcd8 0x69 0xcd3 0x69 0xccb 0x69 0xcc7 0x69 0xcc3 0x69 0xcbc 0x6a 0xcb8 0x6a 0xcb3 0x6a 0xcab 0x6a 0xca7 0x6a 0xca1 0x6a 0xc99 0x6a 0xc92 0x6a 0xc8e 0x6a 0xc89 0x6a 0xc82 0x6a 0xc7c 0x6a 0xc71 0x6a 0xc63 0x6a 0xc55 0x6a 0xc46 0x6a 0xc35 0x6a 0xc2a 0x6a 0xc17 0x6a 0xc17 0x6a 0xc17>;
			battery_profile_t1_num = <0x64>;
			battery_profile_t1 = <0x0 0xfd0 0x2 0xfa8 0x3 0xf95 0x5 0xf89 0x7 0xf7e 0x8 0xf78 0xa 0xf74 0xb 0xf6f 0xd 0xf6c 0xf 0xf65 0x10 0xf5f 0x12 0xf58 0x14 0xf52 0x15 0xf4a 0x17 0xf42 0x19 0xf3a 0x1a 0xf34 0x1c 0xf2a 0x1d 0xf20 0x1f 0xf14 0x21 0xf09 0x22 0xeff 0x24 0xef7 0x26 0xef0 0x27 0xeea 0x29 0xee7 0x2b 0xee0 0x2c 0xedd 0x2e 0xedb 0x2f 0xed6 0x31 0xed4 0x33 0xed1 0x34 0xed0 0x36 0xece 0x38 0xece 0x39 0xecc 0x3b 0xecc 0x3c 0xecb 0x3e 0xecb 0x40 0xec9 0x41 0xec9 0x43 0xec8 0x45 0xec6 0x46 0xec3 0x48 0xec1 0x4a 0xebe 0x4b 0xeb9 0x4d 0xeb6 0x4f 0xeb2 0x50 0xeac 0x52 0xea4 0x53 0xe9e 0x55 0xe96 0x57 0xe8c 0x58 0xe82 0x5a 0xe7c 0x5c 0xe77 0x5d 0xe75 0x5f 0xe73 0x61 0xe70 0x62 0xe69 0x64 0xe4e 0x65 0xe11 0x67 0xdcd 0x68 0xd93 0x68 0xd5a 0x69 0xd23 0x69 0xcf3 0x69 0xcc6 0x69 0xca6 0x69 0xc88 0x69 0xc77 0x6a 0xc64 0x6a 0xc57 0x6a 0xc4e 0x6a 0xc41 0x6a 0xc41 0x6a 0xc41 0x6a 0xc41 0x6a 0xc41 0x6a 0xc41 0x6a 0xc41 0x6a 0xc41 0x6a 0xc41 0x6a 0xc41 0x6a 0xc41 0x6a 0xc41 0x6a 0xc41 0x6a 0xc41 0x6a 0xc41 0x6a 0xc41 0x6a 0xc41 0x6a 0xc41 0x6a 0xc41 0x6a 0xc41 0x6a 0xc41 0x6a 0xc41 0x6a 0xc41 0x6a 0xc41 0x6a 0xc41>;
			battery_profile_t2_num = <0x64>;
			battery_profile_t2 = <0x0 0x1045 0x1 0x1035 0x3 0x1028 0x4 0x1019 0x6 0x100e 0x7 0x1002 0x8 0xff6 0xa 0xff1 0xb 0xfed 0xd 0xfe3 0xe 0xfcf 0xf 0xfb9 0x11 0xfa6 0x12 0xf99 0x13 0xf8f 0x15 0xf87 0x16 0xf83 0x18 0xf80 0x19 0xf7c 0x1a 0xf76 0x1c 0xf6d 0x1d 0xf67 0x1f 0xf5e 0x20 0xf58 0x21 0xf50 0x23 0xf49 0x24 0xf42 0x26 0xf3a 0x27 0xf32 0x28 0xf26 0x2a 0xf19 0x2b 0xf0d 0x2c 0xf03 0x2e 0xefc 0x2f 0xef5 0x31 0xef0 0x32 0xeec 0x33 0xee6 0x35 0xee4 0x36 0xedf 0x38 0xedb 0x39 0xed9 0x3a 0xed4 0x3c 0xed2 0x3d 0xecf 0x3e 0xecd 0x40 0xeca 0x41 0xec8 0x43 0xec6 0x44 0xec5 0x45 0xec3 0x47 0xec3 0x48 0xec1 0x4a 0xebf 0x4b 0xebc 0x4c 0xeb9 0x4e 0xeb5 0x4f 0xeb1 0x51 0xead 0x52 0xea8 0x53 0xea3 0x55 0xe9d 0x56 0xe95 0x57 0xe8c 0x59 0xe85 0x5a 0xe7a 0x5c 0xe71 0x5d 0xe6f 0x5e 0xe6e 0x60 0xe6c 0x61 0xe6a 0x63 0xe64 0x64 0xe43 0x65 0xe03 0x67 0xdaa 0x68 0xd13 0x69 0xc87 0x69 0xc5c 0x69 0xc38 0x69 0xc0f 0x69 0xbf7 0x69 0xbe1 0x69 0xbd5 0x69 0xbd2 0x69 0xbcf 0x69 0xbbd 0x69 0xbb6 0x6a 0xbb0 0x6a 0xba5 0x6a 0xb9d 0x6a 0xb9e 0x6a 0xb9f 0x6a 0xb90 0x6a 0xb86 0x6a 0xb85 0x6a 0xb83 0x6a 0xb80 0x6a 0xb7b 0x6a 0xb78 0x6a 0xb73>;
			battery_profile_t3_num = <0x64>;
			battery_profile_t3 = <0x0 0x1055 0x1 0x1047 0x3 0x1038 0x4 0x102b 0x5 0x101f 0x7 0x1012 0x8 0x1007 0xa 0xffa 0xb 0xfee 0xc 0xfe3 0xe 0xfd8 0xf 0xfd1 0x10 0xfc4 0x12 0xfb6 0x13 0xfaa 0x14 0xfa1 0x16 0xf9b 0x17 0xf92 0x19 0xf89 0x1a 0xf81 0x1b 0xf77 0x1d 0xf70 0x1e 0xf67 0x1f 0xf5f 0x21 0xf59 0x22 0xf50 0x23 0xf49 0x25 0xf42 0x26 0xf3b 0x28 0xf35 0x29 0xf2f 0x2a 0xf27 0x2c 0xf1b 0x2d 0xf0b 0x2e 0xf00 0x30 0xef9 0x31 0xef3 0x32 0xeec 0x34 0xee8 0x35 0xee4 0x37 0xee0 0x38 0xedb 0x39 0xed8 0x3b 0xed5 0x3c 0xed2 0x3d 0xecf 0x3f 0xecb 0x40 0xec9 0x41 0xec6 0x43 0xec3 0x44 0xec2 0x46 0xec0 0x47 0xebf 0x48 0xebc 0x4a 0xeb7 0x4b 0xeaf 0x4c 0xea9 0x4e 0xea7 0x4f 0xea2 0x51 0xe9e 0x52 0xe99 0x53 0xe94 0x55 0xe91 0x56 0xe8c 0x57 0xe83 0x59 0xe7c 0x5a 0xe73 0x5b 0xe69 0x5d 0xe61 0x5e 0xe60 0x5f 0xe60 0x61 0xe5e 0x62 0xe5c 0x64 0xe50 0x65 0xe23 0x66 0xde1 0x68 0xd7e 0x69 0xccf 0x6a 0xc45 0x6a 0xc09 0x6a 0xbde 0x6a 0xbc4 0x6a 0xba6 0x6a 0xba0 0x6a 0xb8c 0x6a 0xb83 0x6a 0xb7e 0x6a 0xb78 0x6a 0xb7b 0x6a 0xb6e 0x6a 0xb6d 0x6a 0xb6a 0x6a 0xb66 0x6a 0xb5e 0x6a 0xb58 0x6a 0xb51 0x6a 0xb4b 0x6a 0xb41 0x6a 0xb39 0x6a 0xb3c>;
			r_profile_t0_num = <0x64>;
			r_profile_t0 = <0x361 0xfd0 0x361 0xfa8 0x37d 0xf95 0x393 0xf89 0x3bb 0xf7e 0x3ff 0xf78 0x4b0 0xf6e 0x53a 0xf6a 0x55f 0xf62 0x56c 0xf5c 0x580 0xf56 0x58c 0xf4e 0x594 0xf46 0x58a 0xf3d 0x594 0xf36 0x58f 0xf2d 0x58a 0xf22 0x591 0xf1a 0x594 0xf10 0x594 0xf06 0x591 0xefe 0x58f 0xef6 0x58c 0xeef 0x587 0xee9 0x591 0xee6 0x591 0xee0 0x5aa 0xede 0x5bc 0xedb 0x5b9 0xed9 0x5cb 0xed6 0x5d0 0xed3 0x5e6 0xed4 0x5eb 0xed3 0x5fd 0xed0 0x5ff 0xed0 0x60c 0xece 0x607 0xecd 0x61b 0xecb 0x634 0xec9 0x64a 0xec7 0x659 0xec5 0x668 0xec0 0x675 0xebc 0x67c 0xeb7 0x690 0xeb3 0x69a 0xeae 0x6ae 0xea7 0x6c5 0xe9e 0x6d1 0xe96 0x6e5 0xe8d 0x6fc 0xe87 0x715 0xe83 0x73d 0xe80 0x771 0xe7b 0x7ad 0xe76 0x7da 0xe70 0x820 0xe5e 0x84b 0xe3f 0x7f3 0xe1c 0x797 0xdf7 0x73d 0xdd1 0x6ea 0xdae 0x695 0xd90 0x657 0xd73 0x60e 0xd5b 0x5d5 0xd43 0x5a8 0xd2d 0x573 0xd1d 0x558 0xd0d 0x53a 0xd00 0x517 0xcf5 0x512 0xceb 0x4ef 0xce4 0x4e5 0xcdd 0x4ec 0xcd8 0x4c9 0xcd3 0x4d8 0xccb 0x4ae 0xcc7 0x4bf 0xcc3 0x4ae 0xcbc 0x4b0 0xcb8 0x4c2 0xcb3 0x4cc 0xcab 0x472 0xca7 0x4ce 0xca1 0x4db 0xc99 0x483 0xc92 0x48d 0xc8e 0x415 0xc89 0x492 0xc82 0x49f 0xc7c 0x53c 0xc71 0x558 0xc63 0x58f 0xc55 0x5af 0xc46 0x5fd 0xc35 0x555 0xc2a 0x675 0xc17 0x675 0xc17 0x675 0xc17>;
			r_profile_t1_num = <0x64>;
			r_profile_t1 = <0x279 0xfd0 0x279 0xfa8 0x2a6 0xf95 0x2ad 0xf89 0x2bc 0xf7e 0x2c9 0xf78 0x2d8 0xf74 0x2ec 0xf6f 0x2f1 0xf6c 0x2fb 0xf65 0x2fb 0xf5f 0x300 0xf58 0x30f 0xf52 0x307 0xf4a 0x30c 0xf42 0x316 0xf3a 0x316 0xf34 0x319 0xf2a 0x31e 0xf20 0x30a 0xf14 0x30a 0xf09 0x302 0xeff 0x30a 0xef7 0x302 0xef0 0x311 0xeea 0x31b 0xee7 0x311 0xee0 0x325 0xedd 0x32a 0xedb 0x32f 0xed6 0x332 0xed4 0x343 0xed1 0x346 0xed0 0x348 0xece 0x361 0xece 0x35f 0xecc 0x370 0xecc 0x37d 0xecb 0x38c 0xecb 0x3a0 0xec9 0x3a5 0xec9 0x3c0 0xec8 0x3c5 0xec6 0x3de 0xec3 0x3eb 0xec1 0x409 0xebe 0x415 0xeb9 0x42e 0xeb6 0x44a 0xeb2 0x459 0xeac 0x479 0xea4 0x4a1 0xe9e 0x4b8 0xe96 0x4e0 0xe8c 0x50f 0xe82 0x535 0xe7c 0x57d 0xe77 0x5b9 0xe75 0x618 0xe73 0x66b 0xe70 0x6d1 0xe69 0x717 0xe4e 0x747 0xe11 0x730 0xdcd 0x698 0xd93 0x618 0xd5a 0x58a 0xd23 0x521 0xcf3 0x4b0 0xcc6 0x44c 0xca6 0x424 0xc88 0x3d4 0xc77 0x3e8 0xc64 0x3bb 0xc57 0x36e 0xc4e 0x3c0 0xc41 0x3c0 0xc41 0x3c0 0xc41 0x3c0 0xc41 0x3c0 0xc41 0x3c0 0xc41 0x3c0 0xc41 0x3c0 0xc41 0x3c0 0xc41 0x3c0 0xc41 0x3c0 0xc41 0x3c0 0xc41 0x3c0 0xc41 0x3c0 0xc41 0x3c0 0xc41 0x3c0 0xc41 0x3c0 0xc41 0x3c0 0xc41 0x3c0 0xc41 0x3c0 0xc41 0x3c0 0xc41 0x3c0 0xc41 0x3c0 0xc41 0x3c0 0xc41 0x3c0 0xc41>;
			r_profile_t2_num = <0x64>;
			r_profile_t2 = <0xfa 0x1045 0xfa 0x1035 0xf3 0x1028 0xf0 0x1019 0xfa 0x100e 0xfa 0x1002 0xf8 0xff6 0x102 0xff1 0x111 0xfed 0x116 0xfe3 0x107 0xfcf 0x109 0xfb9 0x107 0xfa6 0x10c 0xf99 0x107 0xf8f 0x10c 0xf87 0x11b 0xf83 0x120 0xf80 0x122 0xf7c 0x127 0xf76 0x120 0xf6d 0x127 0xf67 0x127 0xf5e 0x12a 0xf58 0x12a 0xf50 0x127 0xf49 0x12a 0xf42 0x12a 0xf3a 0x125 0xf32 0x11b 0xf26 0x10e 0xf19 0xff 0xf0d 0xf3 0xf03 0xf0 0xefc 0xf0 0xef5 0xee 0xef0 0xee 0xeec 0xeb 0xee6 0xf3 0xee4 0xf5 0xedf 0xf5 0xedb 0xfd 0xed9 0xf3 0xed4 0xf8 0xed2 0xfa 0xecf 0xff 0xecd 0xfd 0xeca 0x102 0xec8 0x102 0xec6 0x104 0xec5 0x102 0xec3 0x109 0xec3 0x10c 0xec1 0x10e 0xebf 0x109 0xebc 0x109 0xeb9 0x111 0xeb5 0x111 0xeb1 0x10e 0xead 0x113 0xea8 0x116 0xea3 0x116 0xe9d 0x116 0xe95 0x113 0xe8c 0x11d 0xe85 0x11d 0xe7a 0x111 0xe71 0x11d 0xe6f 0x12f 0xe6e 0x13e 0xe6c 0x154 0xe6a 0x16d 0xe64 0x170 0xe43 0x189 0xe03 0x1ca 0xdaa 0x23f 0xd13 0x42e 0xc87 0x3a5 0xc5c 0x35f 0xc38 0x33e 0xc0f 0x2c6 0xbf7 0x297 0xbe1 0x280 0xbd5 0x23a 0xbd2 0x247 0xbcf 0x28f 0xbbd 0x23f 0xbb6 0x2a3 0xbb0 0x276 0xba5 0x299 0xb9d 0x262 0xb9e 0x210 0xb9f 0x2a1 0xb90 0x2bf 0xb86 0x24e 0xb85 0x1d9 0xb83 0x2b5 0xb80 0x2d5 0xb7b 0x1e3 0xb78 0x1e0 0xb73>;
			r_profile_t3_num = <0x64>;
			r_profile_t3 = <0x8a 0x1055 0x8a 0x1047 0x8a 0x1038 0x8c 0x102b 0x8c 0x101f 0x8f 0x1012 0x8f 0x1007 0x8f 0xffa 0x8c 0xfee 0x8f 0xfe3 0x91 0xfd8 0x9b 0xfd1 0x99 0xfc4 0x9b 0xfb6 0x9b 0xfaa 0x9b 0xfa1 0xa0 0xf9b 0xa3 0xf92 0xa3 0xf89 0xaa 0xf81 0xa3 0xf77 0xad 0xf70 0xad 0xf67 0xaf 0xf5f 0xb4 0xf59 0xb2 0xf50 0xb2 0xf49 0xb4 0xf42 0xb4 0xf3b 0xbe 0xf35 0xbe 0xf2f 0xbe 0xf27 0xb4 0xf1b 0x9e 0xf0b 0x91 0xf00 0x8f 0xef9 0x8c 0xef3 0x8a 0xeec 0x8a 0xee8 0x8f 0xee4 0x91 0xee0 0x91 0xedb 0x91 0xed8 0x96 0xed5 0x99 0xed2 0x99 0xecf 0x9e 0xecb 0x9b 0xec9 0xa0 0xec6 0xa0 0xec3 0xa0 0xec2 0xa3 0xec0 0xa8 0xebf 0xa3 0xebc 0x9e 0xeb7 0x94 0xeaf 0x91 0xea9 0x96 0xea7 0x94 0xea2 0x96 0xe9e 0x96 0xe99 0x94 0xe94 0x9b 0xe91 0x9e 0xe8c 0x96 0xe83 0x9b 0xe7c 0x99 0xe73 0x96 0xe69 0x8f 0xe61 0x96 0xe60 0xa0 0xe60 0xa8 0xe5e 0xb4 0xe5c 0xb4 0xe50 0xaa 0xe23 0xbc 0xde1 0xcd 0xd7e 0x12c 0xccf 0x35a 0xc45 0x30f 0xc09 0x28d 0xbde 0x212 0xbc4 0x203 0xba6 0x1ca 0xba0 0x1f2 0xb8c 0x1db 0xb83 0x1b8 0xb7e 0x1a9 0xb78 0x17f 0xb7b 0x19f 0xb6e 0x14a 0xb6d 0x140 0xb6a 0x145 0xb66 0x181 0xb5e 0x154 0xb58 0x161 0xb51 0x166 0xb4b 0x16d 0xb41 0x181 0xb39 0x140 0xb3c>;
			vbat_remove_detection = <0x0>;
		};

		BAT_NOTIFY {
			compatible = "mediatek,bat_notify";
		};

		bat_comm {
			compatible = "mediatek,battery";
			stop_charging_in_takling = <0x1>;
			talking_recharge_voltage = <0xed8>;
			talking_sync_time = <0x3c>;
			mtk_temperature_recharge_support = <0x1>;
			max_charge_temperature = <0x32>;
			max_charge_temperature_minus_x_degree = <0x2f>;
			min_charge_temperature = <0x0>;
			min_charge_temperature_plus_x_degree = <0x6>;
			err_charge_temperature = <0xff>;
			v_pre2cc_thres = <0xd48>;
			v_cc2topoff_thres = <0xfd2>;
			recharging_voltage = <0x100e>;
			charging_full_current = <0x64>;
			config_usb_if = <0x0>;
			usb_charger_current_suspend = <0x0>;
			usb_charger_current_unconfigured = <0x1b58>;
			usb_charger_current_configured = <0xc350>;
			usb_charger_current = <0xc350>;
			ac_charger_current = <0x25d78>;
			non_std_ac_charger_current = <0xc350>;
			charging_host_charger_current = <0xfde8>;
			apple_0_5a_charger_current = <0xc350>;
			apple_1_0a_charger_current = <0xfde8>;
			apple_2_1a_charger_current = <0x13880>;
			bat_low_temp_protect_enable = <0x0>;
			v_charger_enable = <0x0>;
			v_charger_max = <0x1a2c>;
			v_charger_min = <0x1130>;
			onehundred_percent_tracking_time = <0xa>;
			npercent_tracking_time = <0x14>;
			sync_to_real_tracking_time = <0x3c>;
			v_0percent_tracking = <0xd7a>;
			high_battery_voltage_support = <0x1>;
			ac_charger_input_current = <0x25d78>;
		};

		dsi_te {
			compatible = "mediatek, dsi_te_1-eint";
			status = "disabled";
		};

		type_c_port0 {
			rt-dual,supported_modes = <0x2>;
			rt-tcpc,name = "type_c_port0";
			rt-tcpc,role_def = <0x0>;
			rt-tcpc,rp_level = <0x0>;
			rt-tcpc,notifier_supply_num = <0x1>;
			rt1711,irq_gpio = <0xb 0x4 0x0>;
			rt1711,irq_gpio_under_sp = <0xb 0x51 0x0>;
			rt1711,pcba_ver0 = <0xb 0x3a 0x0>;
			rt1711,pcba_ver1 = <0xb 0x39 0x0>;
			rt1711,pcba_ver2 = <0xb 0x56 0x0>;
			interrupt-parent = <0xc>;
			interrupts = <0x4 0x2>;
			debounce = <0x4 0x0>;
			status = "okay";
		};

		type_c_port0_under_sp {
			interrupt-parent = <0xc>;
			interrupts = <0x51 0x2>;
			debounce = <0x51 0x0>;
			status = "okay";
		};

		charging_ic_rt9458 {
			interrupt-parent = <0xc>;
			interrupts = <0x3 0x2>;
			debounce = <0x3 0x0>;
			status = "okay";
		};
	};

	vcorefs {
		compatible = "mediatek,mt6735-vcorefs";
		clocks = <0x3 0x1 0x3 0x30 0x3 0x33>;
		clock-names = "mux_axi", "syspll_d5", "syspll1_d4";
	};

	rf_clock_buffer {
		compatible = "mediatek,rf_clock_buffer";
		mediatek,clkbuf-quantity = <0x4>;
		mediatek,clkbuf-config = <0x2 0x1 0x0 0x1>;
		status = "okay";
	};

	hwmsensor {
		compatible = "mediatek,hwmsensor";
	};

	gsensor {
		compatible = "mediatek,gsensor";
	};

	als_ps {
		compatible = "mediatek,als_ps";
		pinctrl-names = "pin_default", "pin_cfg";
		pinctrl-0 = <0x8a>;
		pinctrl-1 = <0x8b>;
		status = "okay";
	};

	m_acc_pl {
		compatible = "mediatek,m_acc_pl";
	};

	m_alsps_pl {
		compatible = "mediatek,m_alsps_pl";
	};

	m_batch_pl {
		compatible = "mediatek,m_batch_pl";
	};

	batchsensor {
		compatible = "mediatek,batchsensor";
	};

	gyroscope {
		compatible = "mediatek,gyroscope";
		interrupt-parent = <0xc>;
		interrupts = <0x43 0x8>;
		debounce = <0x43 0x0>;
		status = "okay";
		pinctrl-names = "pin_default", "pin_cfg";
		pinctrl-0 = <0x8c>;
		pinctrl-1 = <0x8d>;
	};

	m_gyro_pl {
		compatible = "mediatek,m_gyro_pl";
	};

	barometer {
		compatible = "mediatek,barometer";
	};

	m_baro_pl {
		compatible = "mediatek,m_baro_pl";
	};

	msensor {
		compatible = "mediatek,msensor";
	};

	m_mag_pl {
		compatible = "mediatek,m_mag_pl";
	};

	orientation {
		compatible = "mediatek,orientation";
	};

	als {
		compatible = "mediatek, als-eint";
		interrupt-parent = <0xc>;
		interrupts = <0x41 0x8>;
		debounce = <0x41 0x0>;
		status = "okay";
	};

	audio_switch {
		compatible = "mediatek,audio_switch";
	};

	gse_1 {
		compatible = "mediatek, gse_1-eint";
		status = "okay";
		interrupt-parent = <0xc>;
		interrupts = <0x42 0x8>;
		debounce = <0x42 0x0>;
	};

	ext_buck_oc {
		compatible = "mediatek, ext_buck_oc-eint";
		status = "okay";
		interrupt-parent = <0xc>;
		interrupts = <0x4e 0x4>;
		debounce = <0x4e 0x0>;
	};

	mt8193ckgen@0 {
		compatible = "mediatek,mt8193-ckgen";
		pinctrl-names = "default", "bus_switch_gpio", "bus_switch_dpi";
		pinctrl-0 = <0x8e>;
		pinctrl-1 = <0x8f>;
		pinctrl-2 = <0x90>;
		bus_switch_pin = <0xb 0x0 0x0>;
		status = "okay";
	};

	multibridge {
		compatible = "mediatek,multibridge";
	};

	trusty {
		compatible = "android,trusty-smc-v1";
		ranges;
		#address-cells = <0x2>;
		#size-cells = <0x2>;

		irq {
			compatible = "android,trusty-irq-v1";
			ppi-interrupt-parent = <0x1>;
		};

		log {
			compatible = "android,trusty-log-v1";
		};

		virtio {
			compatible = "android,trusty-virtio-v1";
		};

		mtee {
			compatible = "mediatek,trusty-mtee-v1";
		};
	};

	lcm_params {
		compatible = "mediatek,lcm_params-r63417_fhd_dsi_cmd_truly_nt50358_drv";
		lcm_params-types = <0x2 0x0 0x0 0x0>;
		lcm_params-resolution = <0x438 0x780>;
		lcm_params-io_select_mode;
		lcm_params-dbi-port;
		lcm_params-dbi-clock_freq;
		lcm_params-dbi-data_width;
		lcm_params-dbi-data_format;
		lcm_params-dbi-cpu_write_bits;
		lcm_params-dbi-io_driving_current;
		lcm_params-dbi-msb_io_driving_current;
		lcm_params-dbi-ctrl_io_driving_current;
		lcm_params-dbi-te_mode;
		lcm_params-dbi-te_edge_polarity;
		lcm_params-dbi-te_hs_delay_cnt;
		lcm_params-dbi-te_vs_width_cnt;
		lcm_params-dbi-te_vs_width_cnt_div;
		lcm_params-dbi-serial-params0;
		lcm_params-dbi-serial-params1;
		lcm_params-dbi-serial-params2;
		lcm_params-dbi-parallel-params0;
		lcm_params-dbi-parallel-params1;
		lcm_params-dpi-mipi_pll_clk_ref;
		lcm_params-dpi-mipi_pll_clk_div1;
		lcm_params-dpi-mipi_pll_clk_div2;
		lcm_params-dpi-mipi_pll_clk_fbk_div;
		lcm_params-dpi-dpi_clk_div;
		lcm_params-dpi-dpi_clk_duty;
		lcm_params-dpi-PLL_CLOCK;
		lcm_params-dpi-dpi_clock;
		lcm_params-dpi-ssc_disable;
		lcm_params-dpi-ssc_range;
		lcm_params-dpi-width;
		lcm_params-dpi-height;
		lcm_params-dpi-bg_width;
		lcm_params-dpi-bg_height;
		lcm_params-dpi-clk_pol;
		lcm_params-dpi-de_pol;
		lcm_params-dpi-vsync_pol;
		lcm_params-dpi-hsync_pol;
		lcm_params-dpi-hsync_pulse_width;
		lcm_params-dpi-hsync_back_porch;
		lcm_params-dpi-hsync_front_porch;
		lcm_params-dpi-vsync_pulse_width;
		lcm_params-dpi-vsync_back_porch;
		lcm_params-dpi-vsync_front_porch;
		lcm_params-dpi-format;
		lcm_params-dpi-rgb_order;
		lcm_params-dpi-is_serial_output;
		lcm_params-dpi-i2x_en;
		lcm_params-dpi-i2x_edge;
		lcm_params-dpi-embsync;
		lcm_params-dpi-lvds_tx_en;
		lcm_params-dpi-bit_swap;
		lcm_params-dpi-intermediat_buffer_num;
		lcm_params-dpi-io_driving_current;
		lcm_params-dpi-lsb_io_driving_current;
		lcm_params-dsi-mode = <0x0>;
		lcm_params-dsi-switch_mode = <0x2>;
		lcm_params-dsi-DSI_WMEM_CONTI;
		lcm_params-dsi-DSI_RMEM_CONTI;
		lcm_params-dsi-VC_NUM;
		lcm_params-dsi-lane_num = <0x4>;
		lcm_params-dsi-data_format = <0x2 0x0 0x0 0x2>;
		lcm_params-dsi-intermediat_buffer_num;
		lcm_params-dsi-ps = <0x2>;
		lcm_params-dsi-word_count;
		lcm_params-dsi-packet_size = <0x100>;
		lcm_params-dsi-vertical_sync_active = <0x2>;
		lcm_params-dsi-vertical_backporch = <0x8>;
		lcm_params-dsi-vertical_frontporch = <0xa>;
		lcm_params-dsi-vertical_frontporch_for_low_power;
		lcm_params-dsi-vertical_active_line = <0x780>;
		lcm_params-dsi-horizontal_sync_active = <0xa>;
		lcm_params-dsi-horizontal_backporch = <0x3c>;
		lcm_params-dsi-horizontal_frontporch = <0x64>;
		lcm_params-dsi-horizontal_blanking_pixel;
		lcm_params-dsi-horizontal_active_pixel = <0x438>;
		lcm_params-dsi-horizontal_bllp;
		lcm_params-dsi-line_byte;
		lcm_params-dsi-horizontal_sync_active_byte;
		lcm_params-dsi-horizontal_backportch_byte;
		lcm_params-dsi-horizontal_frontporch_byte;
		lcm_params-dsi-rgb_byte;
		lcm_params-dsi-horizontal_sync_active_word_count;
		lcm_params-dsi-horizontal_backporch_word_count;
		lcm_params-dsi-horizontal_frontporch_word_count;
		lcm_params-dsi-HS_TRAIL;
		lcm_params-dsi-ZERO;
		lcm_params-dsi-HS_PRPR;
		lcm_params-dsi-LPX;
		lcm_params-dsi-TA_SACK;
		lcm_params-dsi-TA_GET;
		lcm_params-dsi-TA_SURE;
		lcm_params-dsi-TA_GO;
		lcm_params-dsi-CLK_TRAIL;
		lcm_params-dsi-CLK_ZERO;
		lcm_params-dsi-LPX_WAIT;
		lcm_params-dsi-CONT_DET;
		lcm_params-dsi-CLK_HS_PRPR;
		lcm_params-dsi-CLK_HS_POST;
		lcm_params-dsi-DA_HS_EXIT;
		lcm_params-dsi-CLK_HS_EXIT;
		lcm_params-dsi-pll_select;
		lcm_params-dsi-pll_div1;
		lcm_params-dsi-pll_div2;
		lcm_params-dsi-fbk_div;
		lcm_params-dsi-fbk_sel;
		lcm_params-dsi-rg_bir;
		lcm_params-dsi-rg_bic;
		lcm_params-dsi-rg_bp;
		lcm_params-dsi-pll_clock = <0x1c2>;
		lcm_params-dsi-dsi_clock;
		lcm_params-dsi-ssc_disable;
		lcm_params-dsi-ssc_range;
		lcm_params-dsi-compatibility_for_nvk;
		lcm_params-dsi-cont_clock;
		lcm_params-dsi-ufoe_enable;
		lcm_params-dsi-ufoe_params;
		lcm_params-dsi-edp_panel;
		lcm_params-dsi-customization_esd_check_enable = <0x0>;
		lcm_params-dsi-esd_check_enable = <0x1>;
		lcm_params-dsi-lcm_int_te_monitor;
		lcm_params-dsi-lcm_int_te_period;
		lcm_params-dsi-lcm_ext_te_monitor;
		lcm_params-dsi-lcm_ext_te_enable;
		lcm_params-dsi-noncont_clock;
		lcm_params-dsi-noncont_clock_period;
		lcm_params-dsi-clk_lp_per_line_enable = <0x0>;
		lcm_params-dsi-lcm_esd_check_table0 = <0xa 0x1 0x1c 0x0>;
		lcm_params-dsi-lcm_esd_check_table1;
		lcm_params-dsi-lcm_esd_check_table2;
		lcm_params-dsi-switch_mode_enable = <0x0>;
		lcm_params-dsi-dual_dsi_type;
		lcm_params-dsi-lane_swap_en;
		lcm_params-dsi-lane_swap0;
		lcm_params-dsi-lane_swap1;
		lcm_params-dsi-vertical_vfp_lp;
		lcm_params-physical_width;
		lcm_params-physical_height;
		lcm_params-physical_width_um;
		lcm_params-physical_height_um;
		lcm_params-od_table_size;
		lcm_params-od_table;
	};

	lcm_ops {
		compatible = "mediatek,lcm_ops-r63417_fhd_dsi_cmd_truly_nt50358_drv";
		init = <0x1 0x1 0x1 0x0 0x1 0x2 0x1 0x1 0x1 0x3 0x1 0x1 0x3 0x2 0x1 0xa 0x2 0x1 0x2 0x0 0xa 0x2 0x1 0x2 0x1 0xa 0x3 0x1 0x1 0x1 0x3 0x2 0x1 0x1 0x3 0x1 0x1 0x0 0x3 0x2 0x1 0xa 0x3 0x1 0x1 0x1 0x3 0x2 0x1 0xa 0x4 0x5 0x3 0xb0 0x1 0x0 0x4 0x5 0x3 0xd6 0x1 0x1 0x4 0x5 0x3 0x51 0x1 0xff 0x4 0x5 0x3 0x53 0x1 0xc 0x4 0x5 0x2a 0xc6 0x28 0x77 0x1 0x71 0x7 0x65 0x0 0x0 0x0 0x0 0x0 0x0 0x0 0x0 0x0 0x0 0x0 0x0 0x9 0x19 0x9 0x77 0x1 0x71 0x7 0x65 0x0 0x0 0x0 0x0 0x0 0x0 0x0 0x0 0x0 0x0 0x0 0x0 0x9 0x19 0x9 0x4 0x5 0x20 0xc7 0x1e 0x1 0xc 0x14 0x1e 0x2d 0x3c 0x48 0x58 0x3d 0x44 0x4f 0x5c 0x65 0x6d 0x75 0x1 0xc 0x14 0x1d 0x2c 0x39 0x44 0x54 0x39 0x41 0x4d 0x5a 0x63 0x6b 0x74 0x4 0x5 0x15 0xc8 0x13 0x1 0x0 0xff 0xff 0x0 0xfc 0x0 0x0 0xff 0xff 0x0 0xfc 0x0 0x0 0xff 0xff 0x0 0xfc 0x0 0x4 0x5 0x3 0x35 0x1 0x0 0x4 0x5 0x4 0xb6 0x2 0x3a 0xd3 0x4 0x5 0x2 0x29 0x0 0x4 0x5 0x2 0x11 0x0 0x3 0x2 0x1 0x78>;
		compare_id = <0x3 0x1 0x1 0x1 0x3 0x2 0x1 0x1 0x3 0x1 0x1 0x0 0x3 0x2 0x1 0xa 0x3 0x1 0x1 0x1 0x3 0x2 0x1 0xa 0x4 0x4 0x5 0x1 0x0 0x37 0x2 0x0 0x4 0x7 0x3 0xf4 0x1 0x95>;
		suspend = <0x4 0x5 0x2 0x28 0x0 0x3 0x2 0x1 0x14 0x4 0x5 0x2 0x10 0x0 0x4 0x5 0x3 0xb0 0x1 0x0 0x4 0x5 0x3 0xb1 0x1 0x1 0x3 0x2 0x1 0x50 0x3 0x2 0x1 0xa 0x1 0x1 0x1 0x0 0x1 0x2 0x1 0x1 0x1 0x3 0x1 0x0>;
		backlight = <0x4 0x5 0x3 0x51 0x1 0xff>;
	};

	memory@40000000 {
		device_type = "memory";
		reg = <0x0 0x40000000 0x0 0x1f000000>;
	};

	led@0 {
		compatible = "mediatek,red";
		led_mode = <0x6>;
		data = <0x1>;
		pwm_config = <0x0 0x0 0x0 0x0 0x0>;
	};

	led@1 {
		compatible = "mediatek,green";
		led_mode = <0x6>;
		data = <0x1>;
		pwm_config = <0x0 0x0 0x0 0x0 0x0>;
	};

	led@2 {
		compatible = "mediatek,blue";
		led_mode = <0x6>;
		data = <0x1>;
		pwm_config = <0x0 0x0 0x0 0x0 0x0>;
	};

	led@3 {
		compatible = "mediatek,jogball-backlight";
		led_mode = <0x0>;
		data = <0x1>;
		pwm_config = <0x0 0x0 0x0 0x0 0x0>;
	};

	led@4 {
		compatible = "mediatek,keyboard-backlight";
		led_mode = <0x0>;
		data = <0x1>;
		pwm_config = <0x0 0x0 0x0 0x0 0x0>;
	};

	led@5 {
		compatible = "mediatek,button-backlight";
		led_mode = <0x0>;
		data = <0x1>;
		pwm_config = <0x0 0x0 0x0 0x0 0x0>;
	};

	led@6 {
		compatible = "mediatek,lcd-backlight";
		led_mode = <0x5>;
		data = <0x1>;
		pwm_config = <0x0 0x0 0x0 0x0 0x0>;
	};

	led@7 {
		compatible = "mediatek,rgb";
		led_mode = <0x6>;
		data = <0x1>;
		pwm_config = <0x0 0x0 0x0 0x0 0x0>;
	};

	vibrator@0 {
		compatible = "mediatek,vibrator";
		vib_timer = <0x19>;
		vib_limit = <0x9>;
		vib_vol = <0x7>;
	};

	cust_accel@0 {
		compatible = "mediatek,arima_gsensor";
		i2c_num = <0x2>;
		i2c_addr = <0x18 0x0 0x0 0x0>;
		direction = <0x5>;
		power_id = <0xffff>;
		power_vol = <0x0>;
		firlen = <0x0>;
		is_batch_supported = <0x0>;
	};

	cust_alsps@0 {
		compatible = "mediatek,EPL259x";
		i2c_num = <0x2>;
		i2c_addr = <0x49 0x0 0x0 0x0>;
		polling_mode_ps = <0x0>;
		polling_mode_als = <0x1>;
		power_id = <0xffff>;
		power_vol = <0x0>;
		als_level = <0x0 0x148 0x35d 0x561 0xc35 0x1e29 0x1e57 0x314d 0x5a16 0x6f0e 0x81fa 0xb80c 0xe15e 0xe15e 0xffff>;
		als_value = <0x0 0x85 0x130 0x1f6 0x3ec 0x7d5 0xbf2 0x138d 0x1f48 0x271a 0x2ee0 0x3e80 0x4e20 0x4e20 0x4e20 0x4e20>;
		ps_threshold_high = <0xfa0>;
		ps_threshold_low = <0x5a0>;
		is_batch_supported_ps = <0x0>;
		is_batch_supported_als = <0x0>;
	};

	cust_mag@0 {
		compatible = "mediatek,arima_msensor";
		i2c_num = <0x2>;
		i2c_addr = <0x30 0x0 0x0 0x0>;
		direction = <0x5>;
		power_id = <0xffff>;
		power_vol = <0x0>;
		is_batch_supported = <0x0>;
	};

	cust_gyro@0 {
		compatible = "mediatek,itg1010";
		i2c_num = <0x2>;
		i2c_addr = <0x68 0x0 0x0 0x0>;
		direction = <0x3>;
		power_id = <0xffff>;
		power_vol = <0x0>;
		firlen = <0x0>;
		is_batch_supported = <0x0>;
	};
};
